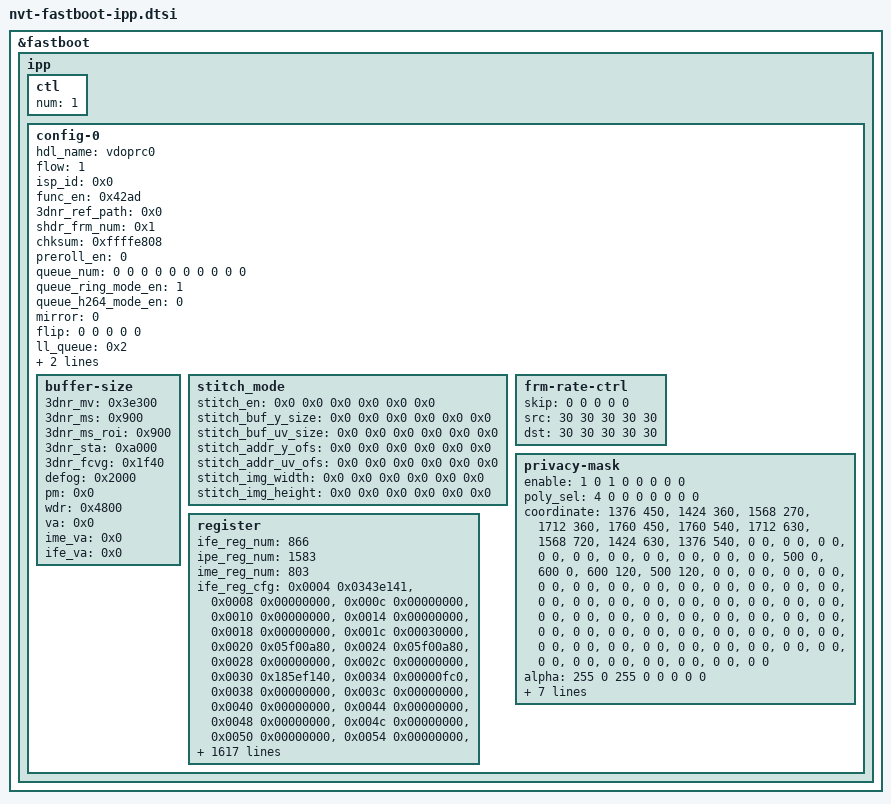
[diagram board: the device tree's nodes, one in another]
&fastboot {
	ipp {
		ctl {
			num = <1>;
		};
		config-0 {
			hdl_name = "vdoprc0";
			flow = <1>;
			isp_id = <0x0>;
			func_en = <0x42ad>;
			3dnr_ref_path = <0x0>;
			shdr_frm_num = <0x1>;
			chksum = <0xffffe808>;
			preroll_en = <0>;
			queue_num = <0 0 0 0 0 0 0 0 0 0 >;
			queue_ring_mode_en = <1>;
			queue_h264_mode_en = <0>;
			mirror = <0>;
			flip = <0 0 0 0 0 >;
			ll_queue = <0x2>;
			rtos_queue = <0x2>;
			buffer_func_en = <0x42ad>;
			buffer-size {
				3dnr_mv = <0x3e300>;
				3dnr_ms = <0x900>;
				3dnr_ms_roi = <0x900>;
				3dnr_sta = <0xa000>;
				3dnr_fcvg = <0x1f40>;
				defog = <0x2000>;
				pm = <0x0>;
				wdr = <0x4800>;
				va = <0x0>;
				ime_va = <0x0>;
				ife_va = <0x0>;
			};
			stitch_mode {
				stitch_en = <0x0 0x0 0x0 0x0 0x0 0x0>;
				stitch_buf_y_size = <0x0 0x0 0x0 0x0 0x0 0x0>;
				stitch_buf_uv_size = <0x0 0x0 0x0 0x0 0x0 0x0>;
				stitch_addr_y_ofs = <0x0 0x0 0x0 0x0 0x0 0x0>;
				stitch_addr_uv_ofs = <0x0 0x0 0x0 0x0 0x0 0x0>;
				stitch_img_width = <0x0 0x0 0x0 0x0 0x0 0x0>;
				stitch_img_height = <0x0 0x0 0x0 0x0 0x0 0x0>;
			};
			frm-rate-ctrl {
				skip = <0 0 0 0 0 >;
				src = <30 30 30 30 30 >;
				dst = <30 30 30 30 30 >;
			};
			privacy-mask {
				enable = <1 0 1 0 0 0 0 0>;
				poly_sel = <4 0 0 0 0 0 0 0>;
				coordinate =
					<1376 450>, <1424 360>, <1568 270>, <1712 360>, <1760 450>, <1760 540>, <1712 630>, <1568 720>, <1424 630>, <1376 540>,
					<0 0>, <0 0>, <0 0>, <0 0>, <0 0>, <0 0>, <0 0>, <0 0>, <0 0>, <0 0>,
					<500 0>, <600 0>, <600 120>, <500 120>, <0 0>, <0 0>, <0 0>, <0 0>, <0 0>, <0 0>,
					<0 0>, <0 0>, <0 0>, <0 0>, <0 0>, <0 0>, <0 0>, <0 0>, <0 0>, <0 0>,
					<0 0>, <0 0>, <0 0>, <0 0>, <0 0>, <0 0>, <0 0>, <0 0>, <0 0>, <0 0>,
					<0 0>, <0 0>, <0 0>, <0 0>, <0 0>, <0 0>, <0 0>, <0 0>, <0 0>, <0 0>,
					<0 0>, <0 0>, <0 0>, <0 0>, <0 0>, <0 0>, <0 0>, <0 0>, <0 0>, <0 0>,
					<0 0>, <0 0>, <0 0>, <0 0>, <0 0>, <0 0>, <0 0>, <0 0>, <0 0>, <0 0>;
				alpha = <255 0 255 0 0 0 0 0>;
				color =
					<78 85 255>,
					<0 0 0>,
					<147 42 20>,
					<0 0 0>,
					<0 0 0>,
					<0 0 0>,
					<0 0 0>,
					<0 0 0>;
				hlw_coordinate =
					<0 0>, <0 0>, <0 0>, <0 0>,
					<0 0>, <0 0>, <0 0>, <0 0>,
					<505 5>, <595 5>, <595 115>, <505 115>,
					<0 0>, <0 0>, <0 0>, <0 0>,
					<0 0>, <0 0>, <0 0>, <0 0>,
					<0 0>, <0 0>, <0 0>, <0 0>,
					<0 0>, <0 0>, <0 0>, <0 0>,
					<0 0>, <0 0>, <0 0>, <0 0>;
			};
			register {
			  ife_reg_num = <866>;
			  ipe_reg_num = <1583>;
			  ime_reg_num = <803>;

			  ife_reg_cfg = 
			    <0x0004 0x0343e141>,
			    <0x0008 0x00000000>,
			    <0x000c 0x00000000>,
			    <0x0010 0x00000000>,
			    <0x0014 0x00000000>,
			    <0x0018 0x00000000>,
			    <0x001c 0x00030000>,
			    <0x0020 0x05f00a80>,
			    <0x0024 0x05f00a80>,
			    <0x0028 0x00000000>,
			    <0x002c 0x00000000>,
			    <0x0030 0x185ef140>,
			    <0x0034 0x00000fc0>,
			    <0x0038 0x00000000>,
			    <0x003c 0x00000000>,
			    <0x0040 0x00000000>,
			    <0x0044 0x00000000>,
			    <0x0048 0x00000000>,
			    <0x004c 0x00000000>,
			    <0x0050 0x00000000>,
			    <0x0054 0x00000000>,
			    <0x0058 0x00000000>,
			    <0x005c 0x00000000>,
			    <0x0060 0x80000002>,
			    <0x0064 0x00000000>,
			    <0x0068 0x00000000>,
			    <0x006c 0x00000100>,
			    <0x0070 0x000fff00>,
			    <0x0074 0x011201bd>,
			    <0x0078 0x02460112>,
			    <0x007c 0x00000112>,
			    <0x0080 0x01000100>,
			    <0x0084 0x01000100>,
			    <0x0088 0x00000100>,
			    <0x008c 0x01000100>,
			    <0x0090 0x01000100>,
			    <0x0094 0x00000100>,
			    <0x0098 0x00000000>,
			    <0x009c 0x00000000>,
			    <0x00a0 0x00000000>,
			    <0x00a4 0x00000000>,
			    <0x00a8 0x00000000>,
			    <0x00ac 0x00000000>,
			    <0x00b0 0x01000100>,
			    <0x00b4 0x01000100>,
			    <0x00b8 0x00000100>,
			    <0x00bc 0x00000000>,
			    <0x00c0 0x00000000>,
			    <0x00c4 0x00000000>,
			    <0x00c8 0x00000000>,
			    <0x00cc 0x00000000>,
			    <0x00d0 0x00000000>,
			    <0x00d4 0x00000000>,
			    <0x00d8 0x00000000>,
			    <0x00dc 0x00000000>,
			    <0x00e0 0x00000000>,
			    <0x00e4 0x00000000>,
			    <0x00e8 0x00000000>,
			    <0x00ec 0x00000000>,
			    <0x00f0 0x0000ffff>,
			    <0x00f4 0x00000000>,
			    <0x00f8 0x00000000>,
			    <0x00fc 0x00000000>,
			    <0x0100 0x00080040>,
			    <0x0104 0x00000000>,
			    <0x0108 0x0911171f>,
			    <0x010c 0x00000307>,
			    <0x0110 0x00000000>,
			    <0x0114 0x00010001>,
			    <0x0118 0x00020001>,
			    <0x011c 0x00000000>,
			    <0x0120 0x00000000>,
			    <0x0124 0x00010001>,
			    <0x0128 0x00020001>,
			    <0x012c 0x00000000>,
			    <0x0130 0x00000000>,
			    <0x0134 0x00010001>,
			    <0x0138 0x00020001>,
			    <0x013c 0x00000000>,
			    <0x0140 0x00000000>,
			    <0x0144 0x00010001>,
			    <0x0148 0x00020001>,
			    <0x014c 0x00000000>,
			    <0x0150 0x00010000>,
			    <0x0154 0x00040003>,
			    <0x0158 0x00070004>,
			    <0x015c 0x00000000>,
			    <0x0160 0x00010000>,
			    <0x0164 0x00040003>,
			    <0x0168 0x00070004>,
			    <0x016c 0x00000000>,
			    <0x0170 0x00010000>,
			    <0x0174 0x00040003>,
			    <0x0178 0x00070004>,
			    <0x017c 0x00000000>,
			    <0x0180 0x00010000>,
			    <0x0184 0x00040003>,
			    <0x0188 0x00070004>,
			    <0x018c 0x00000000>,
			    <0x0190 0x002c62c6>,
			    <0x0194 0x0040c40c>,
			    <0x0198 0x006af6af>,
			    <0x019c 0x0093d93d>,
			    <0x01a0 0x00f41f41>,
			    <0x01a4 0x00010000>,
			    <0x01a8 0x00010033>,
			    <0x01ac 0x86543210>,
			    <0x01b0 0x86543210>,
			    <0x01b4 0x00f00001>,
			    <0x01b8 0x008000a0>,
			    <0x01bc 0x000010ff>,
			    <0x01c0 0x00020000>,
			    <0x01c4 0x00030002>,
			    <0x01c8 0x00040004>,
			    <0x01cc 0x00050004>,
			    <0x01d0 0x00060005>,
			    <0x01d4 0x00060006>,
			    <0x01d8 0x00070006>,
			    <0x01dc 0x00070007>,
			    <0x01e0 0x00000008>,
			    <0x01e4 0x00020000>,
			    <0x01e8 0x00030002>,
			    <0x01ec 0x00040004>,
			    <0x01f0 0x00050004>,
			    <0x01f4 0x00060005>,
			    <0x01f8 0x00060006>,
			    <0x01fc 0x00070006>,
			    <0x0200 0x00070007>,
			    <0x0204 0x00000008>,
			    <0x0208 0x00020000>,
			    <0x020c 0x00030002>,
			    <0x0210 0x00040004>,
			    <0x0214 0x00050004>,
			    <0x0218 0x00060005>,
			    <0x021c 0x00060006>,
			    <0x0220 0x00070006>,
			    <0x0224 0x00070007>,
			    <0x0228 0x00000008>,
			    <0x022c 0x00020000>,
			    <0x0230 0x00030002>,
			    <0x0234 0x00040004>,
			    <0x0238 0x00050004>,
			    <0x023c 0x00060005>,
			    <0x0240 0x00060006>,
			    <0x0244 0x00070006>,
			    <0x0248 0x00070007>,
			    <0x024c 0x00000008>,
			    <0x0250 0x00020000>,
			    <0x0254 0x00030002>,
			    <0x0258 0x00040004>,
			    <0x025c 0x00050004>,
			    <0x0260 0x00060005>,
			    <0x0264 0x00060006>,
			    <0x0268 0x00070006>,
			    <0x026c 0x00070007>,
			    <0x0270 0x00000008>,
			    <0x0274 0x00020000>,
			    <0x0278 0x00030002>,
			    <0x027c 0x00040004>,
			    <0x0280 0x00050004>,
			    <0x0284 0x00060005>,
			    <0x0288 0x00060006>,
			    <0x028c 0x00070006>,
			    <0x0290 0x00070007>,
			    <0x0294 0x00000008>,
			    <0x0298 0x00020000>,
			    <0x029c 0x00030002>,
			    <0x02a0 0x00040004>,
			    <0x02a4 0x00050004>,
			    <0x02a8 0x00060005>,
			    <0x02ac 0x00060006>,
			    <0x02b0 0x00070006>,
			    <0x02b4 0x00070007>,
			    <0x02b8 0x00000008>,
			    <0x02bc 0x00020000>,
			    <0x02c0 0x00030002>,
			    <0x02c4 0x00040004>,
			    <0x02c8 0x00050004>,
			    <0x02cc 0x00060005>,
			    <0x02d0 0x00060006>,
			    <0x02d4 0x00070006>,
			    <0x02d8 0x00070007>,
			    <0x02dc 0x00000008>,
			    <0x02e0 0x02f80540>,
			    <0x02e4 0x02f80540>,
			    <0x02e8 0x02f80540>,
			    <0x02ec 0x02f80540>,
			    <0x02f0 0x002a52a7>,
			    <0x02f4 0x00000001>,
			    <0x02f8 0x00000000>,
			    <0x02fc 0x00000000>,
			    <0x0300 0x00000000>,
			    <0x0304 0x00000000>,
			    <0x0308 0x00000000>,
			    <0x030c 0x00000000>,
			    <0x0310 0x00000000>,
			    <0x0314 0x00000000>,
			    <0x0318 0x00000000>,
			    <0x031c 0x00000000>,
			    <0x0320 0x00000000>,
			    <0x0324 0x00000000>,
			    <0x0328 0x00000000>,
			    <0x032c 0x00000000>,
			    <0x0330 0x00000000>,
			    <0x0334 0x00000000>,
			    <0x0338 0x00000000>,
			    <0x033c 0x00000000>,
			    <0x0340 0x00000000>,
			    <0x0344 0x00000000>,
			    <0x0348 0x00000000>,
			    <0x034c 0x00000000>,
			    <0x0350 0x00000000>,
			    <0x0354 0x00000000>,
			    <0x0358 0x00000000>,
			    <0x035c 0x00000000>,
			    <0x0360 0x00000000>,
			    <0x0364 0x00000000>,
			    <0x0368 0x00000000>,
			    <0x036c 0x00000000>,
			    <0x0370 0x00000000>,
			    <0x0374 0x00000000>,
			    <0x0378 0x00000000>,
			    <0x037c 0x00000000>,
			    <0x0380 0x00000000>,
			    <0x0384 0x00000000>,
			    <0x0388 0x09060301>,
			    <0x038c 0x15120f0d>,
			    <0x0390 0x211e1b18>,
			    <0x0394 0x2d2a2724>,
			    <0x0398 0x00000030>,
			    <0x039c 0x1b181000>,
			    <0x03a0 0x1f1e1c1b>,
			    <0x03a4 0x1c1d1e1f>,
			    <0x03a8 0x0c1a1b1c>,
			    <0x03ac 0x00000004>,
			    <0x03b0 0x00000000>,
			    <0x03b4 0x00000000>,
			    <0x03b8 0x00000000>,
			    <0x03bc 0x00000000>,
			    <0x03c0 0x1f1f1f1f>,
			    <0x03c4 0x1e1e1f1f>,
			    <0x03c8 0x14181c1d>,
			    <0x03cc 0x080a0c10>,
			    <0x03d0 0x06060606>,
			    <0x03d4 0x05050505>,
			    <0x03d8 0x04040404>,
			    <0x03dc 0x20010203>,
			    <0x03e0 0x00000000>,
			    <0x03e4 0x00000000>,
			    <0x03e8 0x00000000>,
			    <0x03ec 0x00000000>,
			    <0x03f0 0x00000000>,
			    <0x03f4 0x00000000>,
			    <0x03f8 0x00000000>,
			    <0x03fc 0x00000000>,
			    <0x0400 0x00000000>,
			    <0x0404 0x00000000>,
			    <0x0408 0x00000000>,
			    <0x040c 0x00000000>,
			    <0x0410 0x00000000>,
			    <0x0414 0x00000000>,
			    <0x0418 0x00000000>,
			    <0x041c 0x00000000>,
			    <0x0420 0x00000000>,
			    <0x0424 0x00000000>,
			    <0x0428 0x00000000>,
			    <0x042c 0x00000000>,
			    <0x0430 0x00000000>,
			    <0x0434 0x00000000>,
			    <0x0438 0x00000000>,
			    <0x043c 0x00000000>,
			    <0x0440 0x00000000>,
			    <0x0444 0x00000000>,
			    <0x0448 0x00000000>,
			    <0x044c 0x00000000>,
			    <0x0450 0x00000000>,
			    <0x0454 0x00000000>,
			    <0x0458 0x00000000>,
			    <0x045c 0x00000000>,
			    <0x0460 0x00000000>,
			    <0x0464 0x00000000>,
			    <0x0468 0x00000000>,
			    <0x046c 0x00000000>,
			    <0x0470 0x00000000>,
			    <0x0474 0x00000000>,
			    <0x0478 0x00000000>,
			    <0x047c 0x00000000>,
			    <0x0480 0x00000000>,
			    <0x0484 0x00000000>,
			    <0x0488 0x00000000>,
			    <0x048c 0x00000000>,
			    <0x0490 0x00000000>,
			    <0x0494 0x00000000>,
			    <0x0498 0x00000000>,
			    <0x049c 0x00000000>,
			    <0x04a0 0x00000000>,
			    <0x04a4 0x00000000>,
			    <0x04a8 0x00000000>,
			    <0x04ac 0x00000000>,
			    <0x04b0 0x00000000>,
			    <0x04b4 0x00000000>,
			    <0x04b8 0x00000000>,
			    <0x04bc 0x00000000>,
			    <0x04c0 0x00000000>,
			    <0x04c4 0x00000000>,
			    <0x04c8 0x00000000>,
			    <0x04cc 0x00000000>,
			    <0x04d0 0x00000000>,
			    <0x04d4 0x00000000>,
			    <0x04d8 0x00000000>,
			    <0x04dc 0x00000000>,
			    <0x04e0 0x00000000>,
			    <0x04e4 0x00000000>,
			    <0x04e8 0x00000000>,
			    <0x04ec 0x00000000>,
			    <0x04f0 0x00000000>,
			    <0x04f4 0x00000000>,
			    <0x04f8 0x00000000>,
			    <0x04fc 0x00000000>,
			    <0x0500 0x00000000>,
			    <0x0504 0x00000000>,
			    <0x0508 0x00000000>,
			    <0x050c 0x00000000>,
			    <0x0510 0x00000000>,
			    <0x0514 0x00000000>,
			    <0x0518 0x00000000>,
			    <0x051c 0x00000000>,
			    <0x0520 0x00000210>,
			    <0x0524 0x02000c00>,
			    <0x0528 0x004000c0>,
			    <0x052c 0x02000c00>,
			    <0x0530 0x004000c0>,
			    <0x0534 0x40000800>,
			    <0x0538 0x40000800>,
			    <0x053c 0x00000100>,
			    <0x0540 0x00000005>,
			    <0x0544 0x0a418820>,
			    <0x0548 0x16a4a0e6>,
			    <0x054c 0x000839ac>,
			    <0x0550 0xff100fff>,
			    <0x0554 0xff100fff>,
			    <0x0558 0x00000000>,
			    <0x055c 0x00000000>,
			    <0x0560 0x00000000>,
			    <0x0564 0x00000000>,
			    <0x0568 0x00000000>,
			    <0x056c 0x00000000>,
			    <0x0570 0x00000000>,
			    <0x0574 0x00000000>,
			    <0x0578 0x00000000>,
			    <0x057c 0x00000000>,
			    <0x0580 0x00000000>,
			    <0x0584 0x00000000>,
			    <0x0588 0x00000000>,
			    <0x058c 0x00000000>,
			    <0x0590 0x00000000>,
			    <0x0594 0x00000000>,
			    <0x0598 0x00000000>,
			    <0x059c 0x00000000>,
			    <0x05a0 0x00000000>,
			    <0x05a4 0x00000000>,
			    <0x05a8 0x00000000>,
			    <0x05ac 0x00000000>,
			    <0x05b0 0x00000000>,
			    <0x05b4 0x00000000>,
			    <0x05b8 0x00000000>,
			    <0x05bc 0x00000000>,
			    <0x05c0 0x00000000>,
			    <0x05c4 0x00000000>,
			    <0x05c8 0x00000000>,
			    <0x05cc 0x00000000>,
			    <0x05d0 0x00000000>,
			    <0x05d4 0x00000000>,
			    <0x05d8 0x00000000>,
			    <0x05dc 0x00000000>,
			    <0x05e0 0x00000000>,
			    <0x05e4 0x00000000>,
			    <0x05e8 0x00000000>,
			    <0x05ec 0x00000000>,
			    <0x05f0 0x00000000>,
			    <0x05f4 0x00000000>,
			    <0x05f8 0x00000000>,
			    <0x05fc 0x00000000>,
			    <0x0600 0x00000000>,
			    <0x0604 0x00000000>,
			    <0x0608 0x00000000>,
			    <0x060c 0x00000000>,
			    <0x0610 0x00000000>,
			    <0x0614 0x00000000>,
			    <0x0618 0x00000000>,
			    <0x061c 0x00000000>,
			    <0x0620 0x00000000>,
			    <0x0624 0x00000000>,
			    <0x0628 0x00000000>,
			    <0x062c 0x00000000>,
			    <0x0630 0x00000000>,
			    <0x0634 0x00000000>,
			    <0x0638 0x00000000>,
			    <0x063c 0x00000000>,
			    <0x0640 0x00000000>,
			    <0x0644 0x00000000>,
			    <0x0648 0x00000000>,
			    <0x064c 0x00000000>,
			    <0x0650 0x00000000>,
			    <0x0654 0x00000000>,
			    <0x0658 0x00000000>,
			    <0x065c 0x00000000>,
			    <0x0660 0x00000000>,
			    <0x0664 0x00000000>,
			    <0x0668 0x00000000>,
			    <0x066c 0x00000000>,
			    <0x0670 0x00000000>,
			    <0x0674 0x00000000>,
			    <0x0678 0x00000000>,
			    <0x067c 0x00000000>,
			    <0x0680 0x00000000>,
			    <0x0684 0x00000000>,
			    <0x0688 0x00000000>,
			    <0x068c 0x00000000>,
			    <0x0690 0x00000000>,
			    <0x0694 0x00000000>,
			    <0x0698 0x00000000>,
			    <0x069c 0x00000000>,
			    <0x06a0 0x00000000>,
			    <0x06a4 0x00000000>,
			    <0x06a8 0x00000000>,
			    <0x06ac 0x00000000>,
			    <0x06b0 0x00000000>,
			    <0x06b4 0x00000000>,
			    <0x06b8 0x00000000>,
			    <0x06bc 0x00000000>,
			    <0x06c0 0x00000000>,
			    <0x06c4 0x00000000>,
			    <0x06c8 0x00000000>,
			    <0x06cc 0x00000000>,
			    <0x06d0 0x00000000>,
			    <0x06d4 0x00000000>,
			    <0x06d8 0x00000000>,
			    <0x06dc 0x00000000>,
			    <0x06e0 0x00000000>,
			    <0x06e4 0x00000000>,
			    <0x06e8 0x00000000>,
			    <0x06ec 0x00000000>,
			    <0x06f0 0x00000000>,
			    <0x06f4 0x00000000>,
			    <0x06f8 0x00000000>,
			    <0x06fc 0x00000000>,
			    <0x0700 0x00000000>,
			    <0x0704 0x00000000>,
			    <0x0708 0x00000000>,
			    <0x070c 0x00000000>,
			    <0x0710 0x01000100>,
			    <0x0714 0x01000100>,
			    <0x0718 0x00000100>,
			    <0x071c 0x00000000>,
			    <0x0720 0x00000000>,
			    <0x0724 0x00000000>,
			    <0x0728 0x00000000>,
			    <0x072c 0x00000000>,
			    <0x0730 0x00000000>,
			    <0x0734 0x00000000>,
			    <0x0738 0x00000000>,
			    <0x073c 0x00000000>,
			    <0x0740 0x00000000>,
			    <0x0744 0x00000000>,
			    <0x0748 0x00000000>,
			    <0x074c 0x00000000>,
			    <0x0750 0x00000000>,
			    <0x0754 0x00000000>,
			    <0x0758 0x00000000>,
			    <0x075c 0x00000000>,
			    <0x0760 0x00000000>,
			    <0x0764 0x00000000>,
			    <0x0768 0x00000000>,
			    <0x076c 0x00000000>,
			    <0x0770 0x00000000>,
			    <0x0774 0x00000000>,
			    <0x0778 0x00000000>,
			    <0x077c 0x00000000>,
			    <0x0780 0x00000000>,
			    <0x0784 0x00000000>,
			    <0x0788 0x00000000>,
			    <0x078c 0x00000000>,
			    <0x0790 0x00000000>,
			    <0x0794 0x00000000>,
			    <0x0798 0x00000000>,
			    <0x079c 0x00000000>,
			    <0x07a0 0x00000000>,
			    <0x07a4 0x00000000>,
			    <0x07a8 0x00000000>,
			    <0x07ac 0x00000000>,
			    <0x07b0 0x00000000>,
			    <0x07b4 0x00000000>,
			    <0x07b8 0x00000000>,
			    <0x07bc 0x00000000>,
			    <0x07c0 0x00000000>,
			    <0x07c4 0x00000000>,
			    <0x07c8 0x00000000>,
			    <0x07cc 0x00000000>,
			    <0x07d0 0x00000000>,
			    <0x07d4 0x00000000>,
			    <0x07d8 0x00000000>,
			    <0x07dc 0x00000000>,
			    <0x07e0 0x00000000>,
			    <0x07e4 0x00000000>,
			    <0x07e8 0x00000000>,
			    <0x07ec 0x00000000>,
			    <0x07f0 0x00000000>,
			    <0x07f4 0x00000000>,
			    <0x07f8 0x00000000>,
			    <0x07fc 0x00000000>,
			    <0x0800 0x00000000>,
			    <0x0804 0x00000000>,
			    <0x0808 0x00000000>,
			    <0x080c 0x00000000>,
			    <0x0810 0x00000000>,
			    <0x0814 0x00000000>,
			    <0x0818 0x00000000>,
			    <0x081c 0x00000000>,
			    <0x0820 0x00000000>,
			    <0x0824 0x00000000>,
			    <0x0828 0x00000000>,
			    <0x082c 0x00000000>,
			    <0x0830 0x00000000>,
			    <0x0834 0x00000000>,
			    <0x0838 0x000002a0>,
			    <0x083c 0x00000000>,
			    <0x0840 0x00000000>,
			    <0x0844 0x00000000>,
			    <0x0848 0x00000000>,
			    <0x084c 0x00000000>,
			    <0x0850 0x00000000>,
			    <0x0854 0x00000000>,
			    <0x0858 0x00000000>,
			    <0x085c 0x00000000>,
			    <0x0860 0x00000007>,
			    <0x0864 0x0f7201ae>,
			    <0x0868 0x0f9e0fe0>,
			    <0x086c 0x0fe6017e>,
			    <0x0870 0x0ef10034>,
			    <0x0874 0x000001db>,
			    <0x0878 0x00000000>,
			    <0x087c 0x725a3c00>,
			    <0x0880 0xab9f9183>,
			    <0x0884 0xd6ccc2b7>,
			    <0x0888 0xf8f0e8df>,
			    <0x088c 0x000000ff>,
			    <0x0890 0x00000000>,
			    <0x0894 0x00000000>,
			    <0x0898 0x00000000>,
			    <0x089c 0x00000000>,
			    <0x08a0 0x00000000>,
			    <0x08a4 0x00000000>,
			    <0x08a8 0x00000000>,
			    <0x08ac 0x00000000>,
			    <0x08b0 0x00000000>,
			    <0x08b4 0x00000000>,
			    <0x08b8 0x00000000>,
			    <0x08bc 0x00000000>,
			    <0x08c0 0x00000000>,
			    <0x08c4 0x00000000>,
			    <0x08c8 0x00000000>,
			    <0x08cc 0x00000000>,
			    <0x08d0 0x00000000>,
			    <0x08d4 0x00000000>,
			    <0x08d8 0x00000000>,
			    <0x08dc 0x00000000>,
			    <0x08e0 0x00000000>,
			    <0x08e4 0x00000000>,
			    <0x08e8 0x00000000>,
			    <0x08ec 0x00000000>,
			    <0x08f0 0x00000000>,
			    <0x08f4 0x00000000>,
			    <0x08f8 0x00000000>,
			    <0x08fc 0x00000000>,
			    <0x0900 0x0000000f>,
			    <0x0904 0x000b111f>,
			    <0x0908 0x1afd4880>,
			    <0x090c 0x00000100>,
			    <0x0910 0x1afd9080>,
			    <0x0914 0x00000100>,
			    <0x0918 0x151c1500>,
			    <0x091c 0x0000030c>,
			    <0x0920 0x00000308>,
			    <0x0924 0x00000000>,
			    <0x0928 0x00000000>,
			    <0x092c 0x00000000>,
			    <0x0930 0x00000000>,
			    <0x0934 0x00000000>,
			    <0x0938 0x00000000>,
			    <0x093c 0x00000054>,
			    <0x0940 0x1565193c>,
			    <0x0944 0x160c160c>,
			    <0x0948 0x55050003>,
			    <0x094c 0x00000000>,
			    <0x0950 0x00000000>,
			    <0x0954 0x00000000>,
			    <0x0958 0x00000000>,
			    <0x095c 0x00000000>,
			    <0x0960 0x00000000>,
			    <0x0964 0x00000000>,
			    <0x0968 0x00000000>,
			    <0x096c 0x00000000>,
			    <0x0970 0x00000000>,
			    <0x0974 0x00000000>,
			    <0x0978 0x00000000>,
			    <0x097c 0x00000000>,
			    <0x0980 0x00000000>,
			    <0x0984 0x00000000>,
			    <0x0988 0x00000000>,
			    <0x098c 0x00000000>,
			    <0x0990 0x00000000>,
			    <0x0994 0x00000000>,
			    <0x0998 0x00000000>,
			    <0x099c 0x00000000>,
			    <0x09a0 0x00000000>,
			    <0x09a4 0x00000000>,
			    <0x09a8 0x00000000>,
			    <0x09ac 0x00000000>,
			    <0x09b0 0x00000000>,
			    <0x09b4 0x00000000>,
			    <0x09b8 0x00000000>,
			    <0x09bc 0x00000000>,
			    <0x09c0 0x00000000>,
			    <0x09c4 0x00000000>,
			    <0x09c8 0x00000000>,
			    <0x09cc 0x00000000>,
			    <0x09d0 0x00000000>,
			    <0x09d4 0x00000000>,
			    <0x09d8 0x00000000>,
			    <0x09dc 0x00000000>,
			    <0x09e0 0x00000000>,
			    <0x09e4 0x00000000>,
			    <0x09e8 0x00000000>,
			    <0x09ec 0x00000000>,
			    <0x09f0 0x00000000>,
			    <0x09f4 0x00000000>,
			    <0x09f8 0x0fb00fb5>,
			    <0x09fc 0x0fa50fab>,
			    <0x0a00 0x0f9a0fa0>,
			    <0x0a04 0x0f8c0f93>,
			    <0x0a08 0x0f7d0f85>,
			    <0x0a0c 0x0f6c0f74>,
			    <0x0a10 0x0f580f62>,
			    <0x0a14 0x0f430f4e>,
			    <0x0a18 0x0f2a0f37>,
			    <0x0a1c 0x0f0f0f1d>,
			    <0x0a20 0x0ef10f00>,
			    <0x0a24 0x0ecf0ee0>,
			    <0x0a28 0x0ea90ebc>,
			    <0x0a2c 0x0e7f0e94>,
			    <0x0a30 0x0e500e68>,
			    <0x0a34 0x0e1c0e37>,
			    <0x0a38 0x0de40e01>,
			    <0x0a3c 0x0da50dc5>,
			    <0x0a40 0x0d620d84>,
			    <0x0a44 0x0d180d3d>,
			    <0x0a48 0x0cc80cf0>,
			    <0x0a4c 0x0c710c9d>,
			    <0x0a50 0x0c150c44>,
			    <0x0a54 0x0bb20be4>,
			    <0x0a58 0x0b4a0b7f>,
			    <0x0a5c 0x0adc0b14>,
			    <0x0a60 0x0a6a0aa4>,
			    <0x0a64 0x09f30a2f>,
			    <0x0a68 0x097809b6>,
			    <0x0a6c 0x08fb093a>,
			    <0x0a70 0x087c08bc>,
			    <0x0a74 0x07fc083c>,
			    <0x0a78 0x000007bc>,
			    <0x0a7c 0x06bf07bc>,
			    <0x0a80 0x04ea05cc>,
			    <0x0a84 0x0366041c>,
			    <0x0a88 0x024302c9>,
			    <0x0a8c 0x017601d3>,
			    <0x0a90 0x00ee012b>,
			    <0x0a94 0x009500bc>,
			    <0x0a98 0x005d0076>,
			    <0x0a9c 0x00000049>,
			    <0x0aa0 0x00000000>,
			    <0x0aa4 0x00000040>,
			    <0x0aa8 0xff000000>,
			    <0x0aac 0x00408003>,
			    <0x0ab0 0x00000200>,
			    <0x0ab4 0x00060006>,
			    <0x0ab8 0x00000000>,
			    <0x0abc 0x00000000>,
			    <0x0ac0 0x00000000>,
			    <0x0ac4 0x00000000>,
			    <0x0ac8 0x00000000>,
			    <0x0acc 0x00000000>,
			    <0x0ad0 0x00000000>,
			    <0x0ad4 0x00000000>,
			    <0x0ad8 0x00000000>,
			    <0x0adc 0x00000000>,
			    <0x0ae0 0x00000000>,
			    <0x0ae4 0x00000000>,
			    <0x0ae8 0x00000000>,
			    <0x0aec 0x00000000>,
			    <0x0af0 0x00000000>,
			    <0x0af4 0x00000000>,
			    <0x0af8 0x00000000>,
			    <0x0afc 0x00000000>,
			    <0x0b00 0x00000000>,
			    <0x0b04 0x00000000>,
			    <0x0b08 0x00000000>,
			    <0x0b0c 0x00000000>,
			    <0x0b10 0x00000000>,
			    <0x0b14 0x00000000>,
			    <0x0b18 0x00000000>,
			    <0x0b1c 0x00000000>,
			    <0x0b20 0x00000000>,
			    <0x0b24 0x00000000>,
			    <0x0b28 0x00000000>,
			    <0x0b2c 0x00000000>,
			    <0x0b30 0x00000000>,
			    <0x0b34 0x00000000>,
			    <0x0b38 0x00000000>,
			    <0x0b3c 0x00000000>,
			    <0x0b40 0x00000000>,
			    <0x0b44 0x00000000>,
			    <0x0b48 0x00000000>,
			    <0x0b4c 0x00000000>,
			    <0x0b50 0x00000000>,
			    <0x0b54 0x00000000>,
			    <0x0b58 0x00000000>,
			    <0x0b5c 0x00000000>,
			    <0x0b60 0x00000000>,
			    <0x0b64 0x00000000>,
			    <0x0b68 0x00000000>,
			    <0x0b6c 0x00000000>,
			    <0x0b70 0x00000000>,
			    <0x0b74 0x00000000>,
			    <0x0b78 0x00000000>,
			    <0x0b7c 0x00000000>,
			    <0x0b80 0x00000000>,
			    <0x0b84 0x00000000>,
			    <0x0b88 0x00000000>,
			    <0x0b8c 0x00000000>,
			    <0x0b90 0x00000000>,
			    <0x0b94 0x00000000>,
			    <0x0b98 0x00000000>,
			    <0x0b9c 0x00000000>,
			    <0x0ba0 0x00000000>,
			    <0x0ba4 0x00000000>,
			    <0x0ba8 0x00000000>,
			    <0x0bac 0x00000000>,
			    <0x0bb0 0x00000000>,
			    <0x0bb4 0x00000000>,
			    <0x0bb8 0x06008001>,
			    <0x0bbc 0x0a000800>,
			    <0x0bc0 0x0c800c00>,
			    <0x0bc4 0x00000dac>,
			    <0x0bc8 0x00000000>,
			    <0x0bcc 0x00000000>,
			    <0x0bd0 0x00000000>,
			    <0x0bd4 0x00000000>,
			    <0x0bd8 0x00000000>,
			    <0x0bdc 0x00000000>,
			    <0x0be0 0x00000000>,
			    <0x0be4 0x00000000>,
			    <0x0be8 0x00000000>,
			    <0x0bec 0x00000000>,
			    <0x0bf0 0x00000000>,
			    <0x0bf4 0x00000000>,
			    <0x0bf8 0x00000000>,
			    <0x0bfc 0x00000000>,
			    <0x0c00 0x00000000>,
			    <0x0c04 0x00000000>,
			    <0x0c08 0x00000000>,
			    <0x0c0c 0x00000000>,
			    <0x0c10 0x00000000>,
			    <0x0c14 0x00000000>,
			    <0x0c18 0x00000000>,
			    <0x0c1c 0x00000000>,
			    <0x0c20 0x00000000>,
			    <0x0c24 0x00000000>,
			    <0x0c28 0x00000000>,
			    <0x0c2c 0x00000000>,
			    <0x0c30 0x00000000>,
			    <0x0c34 0x00000000>,
			    <0x0c38 0x00000000>,
			    <0x0c3c 0x00000000>,
			    <0x0c40 0x00000000>,
			    <0x0c44 0x00000000>,
			    <0x0c48 0x00000000>,
			    <0x0c4c 0x00000000>,
			    <0x0c50 0x00000000>,
			    <0x0c54 0x00000000>,
			    <0x0c58 0x00000000>,
			    <0x0c5c 0x00000000>,
			    <0x0c60 0x00000000>,
			    <0x0c64 0x00000000>,
			    <0x0c68 0x00000000>,
			    <0x0c6c 0x00000000>,
			    <0x0c70 0x00000000>,
			    <0x0c74 0x00000000>,
			    <0x0c78 0x00000000>,
			    <0x0c7c 0x00000000>,
			    <0x0c80 0x00000000>,
			    <0x0c84 0x00000000>,
			    <0x0c88 0x00000000>,
			    <0x0c8c 0x00000000>,
			    <0x0c90 0x00000000>,
			    <0x0c94 0x00000000>,
			    <0x0c98 0x00000000>,
			    <0x0c9c 0x00000000>,
			    <0x0ca0 0x00000000>,
			    <0x0ca4 0x00000000>,
			    <0x0ca8 0x00000000>,
			    <0x0cac 0x00000000>,
			    <0x0cb0 0x00000000>,
			    <0x0cb4 0x00000000>,
			    <0x0cb8 0x00000000>,
			    <0x0cbc 0x00000000>,
			    <0x0cc0 0x00000000>,
			    <0x0cc4 0x00000000>,
			    <0x0cc8 0x00000000>,
			    <0x0ccc 0x00000000>,
			    <0x0cd0 0x00000000>,
			    <0x0cd4 0x00000000>,
			    <0x0cd8 0x00000000>,
			    <0x0cdc 0x00000000>,
			    <0x0ce0 0x00000000>,
			    <0x0ce4 0x00000000>,
			    <0x0ce8 0x00000000>,
			    <0x0cec 0x00000000>,
			    <0x0cf0 0x00000000>,
			    <0x0cf4 0x00000000>,
			    <0x0cf8 0x00000000>,
			    <0x0cfc 0x00000000>,
			    <0x0d00 0x00000000>,
			    <0x0d04 0x00000000>,
			    <0x0d08 0x00000000>,
			    <0x0d0c 0x00000000>,
			    <0x0d10 0x00000000>,
			    <0x0d14 0x00000000>,
			    <0x0d18 0x00000000>,
			    <0x0d1c 0x00000000>,
			    <0x0d20 0x00000000>,
			    <0x0d24 0x00000000>,
			    <0x0d28 0x00000000>,
			    <0x0d2c 0x00000000>,
			    <0x0d30 0x00000000>,
			    <0x0d34 0x00000000>,
			    <0x0d38 0x00000000>,
			    <0x0d3c 0x00000000>,
			    <0x0d40 0x00000000>,
			    <0x0d44 0x00000000>,
			    <0x0d48 0x00000000>,
			    <0x0d4c 0x00000000>,
			    <0x0d50 0x00000000>,
			    <0x0d54 0x00000000>,
			    <0x0d58 0x00000000>,
			    <0x0d5c 0x00000000>,
			    <0x0d60 0x00000000>,
			    <0x0d64 0x00000000>,
			    <0x0d68 0x00000000>,
			    <0x0d6c 0x00000000>,
			    <0x0d70 0x00000000>,
			    <0x0d74 0x00000000>,
			    <0x0d78 0x00000000>,
			    <0x0d7c 0x00000000>,
			    <0x0d80 0x00000000>,
			    <0x0d84 0x00000000>,
			    <0x0d88 0x00000000>;

			  ipe_reg_cfg = 
			    <0x0004 0x00000a05>,
			    <0x0008 0x00017f9b>,
			    <0x000c 0x00000088>,
			    <0x0010 0x00000000>,
			    <0x0014 0x00000000>,
			    <0x0018 0x000005f0>,
			    <0x001c 0x00000000>,
			    <0x0020 0x00000000>,
			    <0x0024 0x00000000>,
			    <0x0028 0x00000000>,
			    <0x002c 0x1aea44ec>,
			    <0x0030 0x00000000>,
			    <0x0034 0x00000000>,
			    <0x0038 0x00000000>,
			    <0x003c 0x00000000>,
			    <0x0040 0x00000000>,
			    <0x0044 0x00000000>,
			    <0x0048 0x00000000>,
			    <0x004c 0x00000000>,
			    <0x0050 0x00014208>,
			    <0x0054 0x00000000>,
			    <0x0058 0x00000000>,
			    <0x005c 0x00000000>,
			    <0x0060 0x00000000>,
			    <0x0064 0x00000000>,
			    <0x0068 0x00000000>,
			    <0x006c 0x00000000>,
			    <0x0070 0x017c05a3>,
			    <0x0074 0x3e2ec02a>,
			    <0x0078 0x00a013dd>,
			    <0x007c 0x0010100a>,
			    <0x0080 0x00181818>,
			    <0x0084 0x00000333>,
			    <0x0088 0x00010004>,
			    <0x008c 0x00008888>,
			    <0x0090 0x88881000>,
			    <0x0094 0x00082028>,
			    <0x0098 0xffc8201f>,
			    <0x009c 0x00a500b6>,
			    <0x00a0 0x00800801>,
			    <0x00a4 0xffff3180>,
			    <0x00a8 0x00010000>,
			    <0x00ac 0x01000100>,
			    <0x00b0 0x00600060>,
			    <0x00b4 0x05080000>,
			    <0x00b8 0x40352d20>,
			    <0x00bc 0x40404040>,
			    <0x00c0 0x40404040>,
			    <0x00c4 0x262c3440>,
			    <0x00c8 0x15020000>,
			    <0x00cc 0x7a573000>,
			    <0x00d0 0xffddb79a>,
			    <0x00d4 0xaac0e0ff>,
			    <0x00d8 0x8088909a>,
			    <0x00dc 0x00000000>,
			    <0x00e0 0x40400001>,
			    <0x00e4 0x0400fc00>,
			    <0x00e8 0x00005020>,
			    <0x00ec 0x0810e032>,
			    <0x00f0 0x41000804>,
			    <0x00f4 0x41000804>,
			    <0x00f8 0x41000804>,
			    <0x00fc 0x00000000>,
			    <0x0100 0x01ae0001>,
			    <0x0104 0x0fe00f72>,
			    <0x0108 0x017e0f9e>,
			    <0x010c 0x00340fe6>,
			    <0x0110 0x01db0ef1>,
			    <0x0114 0x00104080>,
			    <0x0118 0x00000000>,
			    <0x011c 0x00000000>,
			    <0x0120 0x00000000>,
			    <0x0124 0x050a0f14>,
			    <0x0128 0x00000000>,
			    <0x012c 0x00000000>,
			    <0x0130 0x0f0a0500>,
			    <0x0134 0x00000000>,
			    <0x0138 0x10752c4d>,
			    <0x013c 0x120357d5>,
			    <0x0140 0x07af2a80>,
			    <0x0144 0x00000000>,
			    <0x0148 0x28200000>,
			    <0x014c 0x80808080>,
			    <0x0150 0x80808080>,
			    <0x0154 0x80808080>,
			    <0x0158 0x80808080>,
			    <0x015c 0x80808080>,
			    <0x0160 0x80808080>,
			    <0x0164 0x00000000>,
			    <0x0168 0x00000000>,
			    <0x016c 0x00000000>,
			    <0x0170 0x00000000>,
			    <0x0174 0x00000000>,
			    <0x0178 0x00000000>,
			    <0x017c 0x00000000>,
			    <0x0180 0x00000000>,
			    <0x0184 0x00000000>,
			    <0x0188 0x00000000>,
			    <0x018c 0x00000000>,
			    <0x0190 0x00000000>,
			    <0x0194 0x80808080>,
			    <0x0198 0x80808080>,
			    <0x019c 0x80808080>,
			    <0x01a0 0x80808080>,
			    <0x01a4 0x80808080>,
			    <0x01a8 0x80808080>,
			    <0x01ac 0x00820820>,
			    <0x01b0 0x00820820>,
			    <0x01b4 0x00000000>,
			    <0x01b8 0x0002308c>,
			    <0x01bc 0x00000080>,
			    <0x01c0 0x00000000>,
			    <0x01c4 0x00000000>,
			    <0x01c8 0x00ffffff>,
			    <0x01cc 0x00808080>,
			    <0x01d0 0x00000000>,
			    <0x01d4 0x00000000>,
			    <0x01d8 0x00000000>,
			    <0x01dc 0x08020080>,
			    <0x01e0 0x08020080>,
			    <0x01e4 0x08020080>,
			    <0x01e8 0x08020080>,
			    <0x01ec 0x08020080>,
			    <0x01f0 0x00020080>,
			    <0x01f4 0x00000000>,
			    <0x01f8 0x02020202>,
			    <0x01fc 0x00500000>,
			    <0x0200 0x30044301>,
			    <0x0204 0x00000000>,
			    <0x0208 0x00000000>,
			    <0x020c 0x00000000>,
			    <0x0210 0x00000000>,
			    <0x0214 0x00000000>,
			    <0x0218 0x00000000>,
			    <0x021c 0x00000000>,
			    <0x0220 0x00000000>,
			    <0x0224 0x00000000>,
			    <0x0228 0x00000000>,
			    <0x022c 0x00000000>,
			    <0x0230 0x00000000>,
			    <0x0234 0x00000000>,
			    <0x0238 0x00000000>,
			    <0x023c 0x00000000>,
			    <0x0240 0x00000000>,
			    <0x0244 0x00000000>,
			    <0x0248 0x00000000>,
			    <0x024c 0x00000000>,
			    <0x0250 0x00000000>,
			    <0x0254 0x00000000>,
			    <0x0258 0x00000000>,
			    <0x025c 0x00000000>,
			    <0x0260 0x00000000>,
			    <0x0264 0x00000000>,
			    <0x0268 0x00000000>,
			    <0x026c 0x00000000>,
			    <0x0270 0x00000000>,
			    <0x0274 0x00000000>,
			    <0x0278 0x00000000>,
			    <0x027c 0x00000000>,
			    <0x0280 0x00000000>,
			    <0x0284 0x00000000>,
			    <0x0288 0x00000000>,
			    <0x028c 0x00000000>,
			    <0x0290 0x00000000>,
			    <0x0294 0x00000000>,
			    <0x0298 0x00000000>,
			    <0x029c 0x00000000>,
			    <0x02a0 0x00000000>,
			    <0x02a4 0x00000000>,
			    <0x02a8 0x00000000>,
			    <0x02ac 0x00000000>,
			    <0x02b0 0x00000000>,
			    <0x02b4 0x00000000>,
			    <0x02b8 0x00000000>,
			    <0x02bc 0x00000000>,
			    <0x02c0 0x00000000>,
			    <0x02c4 0x00000000>,
			    <0x02c8 0x00000000>,
			    <0x02cc 0x00000000>,
			    <0x02d0 0x00000000>,
			    <0x02d4 0x00000000>,
			    <0x02d8 0x00000000>,
			    <0x02dc 0x00000000>,
			    <0x02e0 0x00000000>,
			    <0x02e4 0x00000000>,
			    <0x02e8 0x00000000>,
			    <0x02ec 0x00000000>,
			    <0x02f0 0x00000000>,
			    <0x02f4 0x00000000>,
			    <0x02f8 0x00000000>,
			    <0x02fc 0x00000000>,
			    <0x0300 0x00000000>,
			    <0x0304 0x00000000>,
			    <0x0308 0x00000000>,
			    <0x030c 0x00000000>,
			    <0x0310 0x0000023f>,
			    <0x0314 0x1afd0880>,
			    <0x0318 0x00000080>,
			    <0x031c 0x1afd2880>,
			    <0x0320 0x00000080>,
			    <0x0324 0x02dd02f4>,
			    <0x0328 0x00056ad6>,
			    <0x032c 0x000595a5>,
			    <0x0330 0x00540053>,
			    <0x0334 0x00000000>,
			    <0x0338 0x00000000>,
			    <0x033c 0x00000000>,
			    <0x0340 0x00000054>,
			    <0x0344 0x00000000>,
			    <0x0348 0x00000000>,
			    <0x034c 0x00000000>,
			    <0x0350 0x00000000>,
			    <0x0354 0x00000000>,
			    <0x0358 0x00000000>,
			    <0x035c 0x00000000>,
			    <0x0360 0x00000000>,
			    <0x0364 0x00000000>,
			    <0x0368 0x00000000>,
			    <0x036c 0x00000000>,
			    <0x0370 0x00000000>,
			    <0x0374 0x00000000>,
			    <0x0378 0x00000000>,
			    <0x037c 0x00000000>,
			    <0x0380 0x00000000>,
			    <0x0384 0x00000000>,
			    <0x0388 0x00000000>,
			    <0x038c 0x00000000>,
			    <0x0390 0x00000000>,
			    <0x0394 0x00000000>,
			    <0x0398 0x00000000>,
			    <0x039c 0x00000000>,
			    <0x03a0 0x00000000>,
			    <0x03a4 0x00000000>,
			    <0x03a8 0x00000000>,
			    <0x03ac 0x00000000>,
			    <0x03b0 0x00000000>,
			    <0x03b4 0x00000000>,
			    <0x03b8 0x00000000>,
			    <0x03bc 0x00000000>,
			    <0x03c0 0x00000000>,
			    <0x03c4 0x00000000>,
			    <0x03c8 0x00000000>,
			    <0x03cc 0x00000000>,
			    <0x03d0 0x00000000>,
			    <0x03d4 0x00000000>,
			    <0x03d8 0x00000000>,
			    <0x03dc 0x00000000>,
			    <0x03e0 0x00000000>,
			    <0x03e4 0x00800000>,
			    <0x03e8 0x54545454>,
			    <0x03ec 0x54545454>,
			    <0x03f0 0x00000054>,
			    <0x03f4 0x00000000>,
			    <0x03f8 0x00000000>,
			    <0x03fc 0x00000000>,
			    <0x0400 0x00000000>,
			    <0x0404 0x00000000>,
			    <0x0408 0x00000000>,
			    <0x040c 0x00000000>,
			    <0x0410 0x00000000>,
			    <0x0414 0x00000000>,
			    <0x0418 0x00000000>,
			    <0x041c 0x00000000>,
			    <0x0420 0x00000000>,
			    <0x0424 0x00000000>,
			    <0x0428 0x00000000>,
			    <0x042c 0x00000000>,
			    <0x0430 0x00000000>,
			    <0x0434 0x00000000>,
			    <0x0438 0x00000000>,
			    <0x043c 0x00000000>,
			    <0x0440 0x00000000>,
			    <0x0444 0x00000000>,
			    <0x0448 0x00000000>,
			    <0x044c 0x00000000>,
			    <0x0450 0x00000000>,
			    <0x0454 0x00000000>,
			    <0x0458 0x00000000>,
			    <0x045c 0x00000000>,
			    <0x0460 0x00000000>,
			    <0x0464 0x00000000>,
			    <0x0468 0x00000000>,
			    <0x046c 0x00000000>,
			    <0x0470 0x00000000>,
			    <0x0474 0x00000000>,
			    <0x0478 0x00000000>,
			    <0x047c 0x00000000>,
			    <0x0480 0x00000000>,
			    <0x0484 0x00000000>,
			    <0x0488 0x00000000>,
			    <0x048c 0x00000000>,
			    <0x0490 0x00000000>,
			    <0x0494 0x00000000>,
			    <0x0498 0x00000000>,
			    <0x049c 0x00000000>,
			    <0x04a0 0x00000000>,
			    <0x04a4 0x00000000>,
			    <0x04a8 0x00000000>,
			    <0x04ac 0x00000000>,
			    <0x04b0 0x00000000>,
			    <0x04b4 0x00000000>,
			    <0x04b8 0x00000000>,
			    <0x04bc 0x00000000>,
			    <0x04c0 0x00000000>,
			    <0x04c4 0x00000000>,
			    <0x04c8 0x00000000>,
			    <0x04cc 0x00000000>,
			    <0x04d0 0x00000000>,
			    <0x04d4 0x00000000>,
			    <0x04d8 0x00000000>,
			    <0x04dc 0x00000000>,
			    <0x04e0 0x00000000>,
			    <0x04e4 0x00000000>,
			    <0x04e8 0x00000000>,
			    <0x04ec 0x00000000>,
			    <0x04f0 0x00000000>,
			    <0x04f4 0x00000000>,
			    <0x04f8 0x00000000>,
			    <0x04fc 0x00000000>,
			    <0x0500 0x00000000>,
			    <0x0504 0x00000000>,
			    <0x0508 0x00000000>,
			    <0x050c 0x00000000>,
			    <0x0510 0x00000000>,
			    <0x0514 0x00000000>,
			    <0x0518 0x00000000>,
			    <0x051c 0x00000000>,
			    <0x0520 0x00000000>,
			    <0x0524 0x00000000>,
			    <0x0528 0x00000000>,
			    <0x052c 0x00000000>,
			    <0x0530 0x00000000>,
			    <0x0534 0x00000000>,
			    <0x0538 0x00000000>,
			    <0x053c 0x00000000>,
			    <0x0540 0x00000000>,
			    <0x0544 0x00000000>,
			    <0x0548 0x00000000>,
			    <0x054c 0x00000000>,
			    <0x0550 0x00000000>,
			    <0x0554 0x00000000>,
			    <0x0558 0x00000000>,
			    <0x055c 0x00000000>,
			    <0x0560 0x00000000>,
			    <0x0564 0x00000000>,
			    <0x0568 0x00000000>,
			    <0x056c 0x00000000>,
			    <0x0570 0x00000000>,
			    <0x0574 0x00000000>,
			    <0x0578 0x00000000>,
			    <0x057c 0x00000000>,
			    <0x0580 0x00000000>,
			    <0x0584 0x00000000>,
			    <0x0588 0x00000000>,
			    <0x058c 0x00000000>,
			    <0x0590 0x00000000>,
			    <0x0594 0x00000000>,
			    <0x0598 0x00000000>,
			    <0x059c 0x00000000>,
			    <0x05a0 0x00000000>,
			    <0x05a4 0x00000000>,
			    <0x05a8 0x00000000>,
			    <0x05ac 0x00000000>,
			    <0x05b0 0x00000000>,
			    <0x05b4 0x00000000>,
			    <0x05b8 0x00000000>,
			    <0x05bc 0x00000000>,
			    <0x05c0 0x00000000>,
			    <0x05c4 0x00000000>,
			    <0x05c8 0x00000000>,
			    <0x05cc 0x00000000>,
			    <0x05d0 0x00000000>,
			    <0x05d4 0x00000000>,
			    <0x05d8 0x00000000>,
			    <0x05dc 0x00000000>,
			    <0x05e0 0x00000000>,
			    <0x05e4 0x00000000>,
			    <0x05e8 0x00000000>,
			    <0x05ec 0x00000000>,
			    <0x05f0 0x00000000>,
			    <0x05f4 0x00000000>,
			    <0x05f8 0x00000000>,
			    <0x05fc 0x00000000>,
			    <0x0600 0x00000000>,
			    <0x0604 0x00000000>,
			    <0x0608 0x00000000>,
			    <0x060c 0x00000000>,
			    <0x0610 0x00000000>,
			    <0x0614 0x00000000>,
			    <0x0618 0x00000000>,
			    <0x061c 0x00000000>,
			    <0x0620 0x00000000>,
			    <0x0624 0x00000000>,
			    <0x0628 0x00000000>,
			    <0x062c 0x00000000>,
			    <0x0630 0x00000000>,
			    <0x0634 0x00000000>,
			    <0x0638 0x00000000>,
			    <0x063c 0x00000000>,
			    <0x0640 0x00000000>,
			    <0x0644 0x00000000>,
			    <0x0648 0x00000000>,
			    <0x064c 0x00000000>,
			    <0x0650 0x00000000>,
			    <0x0654 0x00000000>,
			    <0x0658 0x00000000>,
			    <0x065c 0x00000000>,
			    <0x0660 0x00000000>,
			    <0x0664 0x00000000>,
			    <0x0668 0x00000000>,
			    <0x066c 0x00000000>,
			    <0x0670 0x00000000>,
			    <0x0674 0x00000000>,
			    <0x0678 0x00000000>,
			    <0x067c 0x00000000>,
			    <0x0680 0x00000000>,
			    <0x0684 0x00000000>,
			    <0x0688 0x00000000>,
			    <0x068c 0x00000000>,
			    <0x0690 0x00000000>,
			    <0x0694 0x00000000>,
			    <0x0698 0x00000000>,
			    <0x069c 0x00000000>,
			    <0x06a0 0x00000000>,
			    <0x06a4 0x00000000>,
			    <0x06a8 0x00000000>,
			    <0x06ac 0x00000000>,
			    <0x06b0 0x00000000>,
			    <0x06b4 0x00000000>,
			    <0x06b8 0x00000000>,
			    <0x06bc 0x00000000>,
			    <0x06c0 0x00000000>,
			    <0x06c4 0x00000000>,
			    <0x06c8 0x00000000>,
			    <0x06cc 0x00000000>,
			    <0x06d0 0x00000000>,
			    <0x06d4 0x00000000>,
			    <0x06d8 0x00000000>,
			    <0x06dc 0x00000000>,
			    <0x06e0 0x00000000>,
			    <0x06e4 0x00000000>,
			    <0x06e8 0x00000000>,
			    <0x06ec 0x00000000>,
			    <0x06f0 0x00000000>,
			    <0x06f4 0x00000000>,
			    <0x06f8 0x00000000>,
			    <0x06fc 0x00000000>,
			    <0x0700 0x00000000>,
			    <0x0704 0x00000000>,
			    <0x0708 0x00000000>,
			    <0x070c 0x00000000>,
			    <0x0710 0x00000000>,
			    <0x0714 0x00000000>,
			    <0x0718 0x00000000>,
			    <0x071c 0x00000000>,
			    <0x0720 0x00000000>,
			    <0x0724 0x00000000>,
			    <0x0728 0x00000000>,
			    <0x072c 0x00000000>,
			    <0x0730 0x00000000>,
			    <0x0734 0x00000000>,
			    <0x0738 0x00000000>,
			    <0x073c 0x00000000>,
			    <0x0740 0x00000000>,
			    <0x0744 0x00000000>,
			    <0x0748 0x00000000>,
			    <0x074c 0x00000000>,
			    <0x0750 0x00000000>,
			    <0x0754 0x00000000>,
			    <0x0758 0x00000000>,
			    <0x075c 0x00000000>,
			    <0x0760 0x00000000>,
			    <0x0764 0x00000000>,
			    <0x0768 0x00000000>,
			    <0x076c 0x00000000>,
			    <0x0770 0x00000000>,
			    <0x0774 0x00000000>,
			    <0x0778 0x00000000>,
			    <0x077c 0x00000000>,
			    <0x0780 0x00000000>,
			    <0x0784 0x00000000>,
			    <0x0788 0x00000000>,
			    <0x078c 0x00000000>,
			    <0x0790 0x00000000>,
			    <0x0794 0x00000000>,
			    <0x0798 0x00000000>,
			    <0x079c 0x00000000>,
			    <0x07a0 0x00000000>,
			    <0x07a4 0x00000000>,
			    <0x07a8 0x00000000>,
			    <0x07ac 0x00000000>,
			    <0x07b0 0x00000000>,
			    <0x07b4 0x00000000>,
			    <0x07b8 0x00000000>,
			    <0x07bc 0x00000000>,
			    <0x07c0 0x00000000>,
			    <0x07c4 0x00000000>,
			    <0x07c8 0x00000000>,
			    <0x07cc 0x00000000>,
			    <0x07d0 0x00000000>,
			    <0x07d4 0x00000000>,
			    <0x07d8 0x00000000>,
			    <0x07dc 0x00000000>,
			    <0x07e0 0x00000000>,
			    <0x07e4 0x00000000>,
			    <0x07e8 0x00000000>,
			    <0x07ec 0x00000000>,
			    <0x07f0 0x00000000>,
			    <0x07f4 0x00000000>,
			    <0x07f8 0x00000000>,
			    <0x07fc 0x00000000>,
			    <0x0800 0x00000000>,
			    <0x0804 0x00000000>,
			    <0x0808 0x00000000>,
			    <0x080c 0x00000000>,
			    <0x0810 0x00000000>,
			    <0x0814 0x00000000>,
			    <0x0818 0x00000000>,
			    <0x081c 0x00000000>,
			    <0x0820 0x00000000>,
			    <0x0824 0x00000000>,
			    <0x0828 0x00000000>,
			    <0x082c 0x00000000>,
			    <0x0830 0x00000000>,
			    <0x0834 0x00000000>,
			    <0x0838 0x00000000>,
			    <0x083c 0x00000000>,
			    <0x0840 0x00000000>,
			    <0x0844 0x00000000>,
			    <0x0848 0x00000000>,
			    <0x084c 0x00000000>,
			    <0x0850 0x00000000>,
			    <0x0854 0x00000000>,
			    <0x0858 0x00000000>,
			    <0x085c 0x00000000>,
			    <0x0860 0x00000000>,
			    <0x0864 0x00000000>,
			    <0x0868 0x00000000>,
			    <0x086c 0x00000000>,
			    <0x0870 0x00000000>,
			    <0x0874 0x00000000>,
			    <0x0878 0x00000000>,
			    <0x087c 0x00000000>,
			    <0x0880 0x00000000>,
			    <0x0884 0x00000000>,
			    <0x0888 0x00000000>,
			    <0x088c 0x00000000>,
			    <0x0890 0x00000000>,
			    <0x0894 0x00000000>,
			    <0x0898 0x00000000>,
			    <0x089c 0x00000000>,
			    <0x08a0 0x08b12400>,
			    <0x08a4 0x1113c4c6>,
			    <0x08a8 0x16853530>,
			    <0x08ac 0x1b166d82>,
			    <0x08b0 0x1ed76dc7>,
			    <0x08b4 0x21b835fe>,
			    <0x08b8 0x2448da29>,
			    <0x08bc 0x26d97e52>,
			    <0x08c0 0x293a1e7a>,
			    <0x08c4 0x2b9ab2a0>,
			    <0x08c8 0x2ddb46c5>,
			    <0x08cc 0x2ffbd2e8>,
			    <0x08d0 0x31dc4f09>,
			    <0x08d4 0x33acc326>,
			    <0x08d8 0x356d3743>,
			    <0x08dc 0x372da35f>,
			    <0x08e0 0x38ce137b>,
			    <0x08e4 0x3a6e7b95>,
			    <0x08e8 0x3bfedfaf>,
			    <0x08ec 0x3d8f43c8>,
			    <0x08f0 0x3effa3e0>,
			    <0x08f4 0x000ffff7>,
			    <0x08f8 0x00000000>,
			    <0x08fc 0x00000000>,
			    <0x0900 0x00000001>,
			    <0x0904 0x00000000>,
			    <0x0908 0x00000000>,
			    <0x090c 0x00000000>,
			    <0x0910 0x00000000>,
			    <0x0914 0x000a0028>,
			    <0x0918 0x80000000>,
			    <0x091c 0x00000000>,
			    <0x0920 0xf8888888>,
			    <0x0924 0x485f7880>,
			    <0x0928 0x2428303a>,
			    <0x092c 0x20202020>,
			    <0x0930 0x20202020>,
			    <0x0934 0x00a00020>,
			    <0x0938 0x00014008>,
			    <0x093c 0x122347ff>,
			    <0x0940 0x00000111>,
			    <0x0944 0x40081007>,
			    <0x0948 0x00408003>,
			    <0x094c 0x00cc00cc>,
			    <0x0950 0xa80080e6>,
			    <0x0954 0x00800080>,
			    <0x0958 0x00010080>,
			    <0x095c 0x00000100>,
			    <0x0960 0xffffe0c0>,
			    <0x0964 0x00000000>,
			    <0x0968 0x00000000>,
			    <0x096c 0x00000000>,
			    <0x0970 0x00000000>,
			    <0x0974 0x000002a0>,
			    <0x0978 0x00000000>,
			    <0x097c 0x00000000>,
			    <0x0980 0x00000000>,
			    <0x0984 0x00000000>,
			    <0x0988 0x00000000>,
			    <0x098c 0x00000000>,
			    <0x0990 0x00000000>,
			    <0x0994 0x00000000>,
			    <0x0998 0x00000000>,
			    <0x099c 0x00000000>,
			    <0x09a0 0x00000000>,
			    <0x09a4 0x00000000>,
			    <0x09a8 0x00000000>,
			    <0x09ac 0x00000000>,
			    <0x09b0 0x00000000>,
			    <0x09b4 0x00000000>,
			    <0x09b8 0x00000000>,
			    <0x09bc 0x00000000>,
			    <0x09c0 0x00000000>,
			    <0x09c4 0x00000000>,
			    <0x09c8 0x00000000>,
			    <0x09cc 0x00000000>,
			    <0x09d0 0x00000000>,
			    <0x09d4 0x00000000>,
			    <0x09d8 0x00000000>,
			    <0x09dc 0x00000000>,
			    <0x09e0 0x00000000>,
			    <0x09e4 0x00000000>,
			    <0x09e8 0x00000000>,
			    <0x09ec 0x00000000>,
			    <0x09f0 0x00000000>,
			    <0x09f4 0x00000000>,
			    <0x09f8 0x00000000>,
			    <0x09fc 0x00000000>,
			    <0x0a00 0x00000000>,
			    <0x0a04 0x00000000>,
			    <0x0a08 0x00000000>,
			    <0x0a0c 0x00000000>,
			    <0x0a10 0x00000000>,
			    <0x0a14 0x00000000>,
			    <0x0a18 0x00000000>,
			    <0x0a1c 0x00000000>,
			    <0x0a20 0x00000000>,
			    <0x0a24 0x00000000>,
			    <0x0a28 0x00000000>,
			    <0x0a2c 0x00000000>,
			    <0x0a30 0x00000000>,
			    <0x0a34 0x00000000>,
			    <0x0a38 0x00000000>,
			    <0x0a3c 0x00000000>,
			    <0x0a40 0x00000000>,
			    <0x0a44 0x00000000>,
			    <0x0a48 0x00000000>,
			    <0x0a4c 0x00000000>,
			    <0x0a50 0x00000000>,
			    <0x0a54 0x00000000>,
			    <0x0a58 0x00000000>,
			    <0x0a5c 0x00000000>,
			    <0x0a60 0x00000000>,
			    <0x0a64 0x00000000>,
			    <0x0a68 0x00000000>,
			    <0x0a6c 0x00000000>,
			    <0x0a70 0x00000000>,
			    <0x0a74 0x00000000>,
			    <0x0a78 0x00000000>,
			    <0x0a7c 0x00000000>,
			    <0x0a80 0x00000000>,
			    <0x0a84 0x00000000>,
			    <0x0a88 0x00000000>,
			    <0x0a8c 0x00000000>,
			    <0x0a90 0x00000000>,
			    <0x0a94 0x00000000>,
			    <0x0a98 0x00000000>,
			    <0x0a9c 0x00000000>,
			    <0x0aa0 0x00000000>,
			    <0x0aa4 0x00000000>,
			    <0x0aa8 0x00000000>,
			    <0x0aac 0x00000000>,
			    <0x0ab0 0x00000000>,
			    <0x0ab4 0x00000000>,
			    <0x0ab8 0x00000000>,
			    <0x0abc 0x00000000>,
			    <0x0ac0 0x00000000>,
			    <0x0ac4 0x00000000>,
			    <0x0ac8 0x00000000>,
			    <0x0acc 0x00000000>,
			    <0x0ad0 0x00000000>,
			    <0x0ad4 0x00000000>,
			    <0x0ad8 0x00000000>,
			    <0x0adc 0x00000000>,
			    <0x0ae0 0x00000000>,
			    <0x0ae4 0x00000000>,
			    <0x0ae8 0x00000000>,
			    <0x0aec 0x00000000>,
			    <0x0af0 0x00000000>,
			    <0x0af4 0x00000000>,
			    <0x0af8 0x00000000>,
			    <0x0afc 0x00000000>,
			    <0x0b00 0x00000000>,
			    <0x0b04 0x00000000>,
			    <0x0b08 0x00000000>,
			    <0x0b0c 0x00000000>,
			    <0x0b10 0x00000000>,
			    <0x0b14 0x00000000>,
			    <0x0b18 0x00000000>,
			    <0x0b1c 0x00000000>,
			    <0x0b20 0x00000000>,
			    <0x0b24 0x00000000>,
			    <0x0b28 0x00000000>,
			    <0x0b2c 0x00000000>,
			    <0x0b30 0x00000000>,
			    <0x0b34 0x00000000>,
			    <0x0b38 0x00000000>,
			    <0x0b3c 0x00000000>,
			    <0x0b40 0x00000000>,
			    <0x0b44 0x00000000>,
			    <0x0b48 0x00000000>,
			    <0x0b4c 0x00000000>,
			    <0x0b50 0x00000000>,
			    <0x0b54 0x00000000>,
			    <0x0b58 0x00000000>,
			    <0x0b5c 0x00000000>,
			    <0x0b60 0x00000000>,
			    <0x0b64 0x00000000>,
			    <0x0b68 0x00000000>,
			    <0x0b6c 0x00000000>,
			    <0x0b70 0x00000000>,
			    <0x0b74 0x00000000>,
			    <0x0b78 0x00000000>,
			    <0x0b7c 0x00000000>,
			    <0x0b80 0x00000000>,
			    <0x0b84 0x00000000>,
			    <0x0b88 0x00000000>,
			    <0x0b8c 0x00000000>,
			    <0x0b90 0x00000000>,
			    <0x0b94 0x00000000>,
			    <0x0b98 0x00000000>,
			    <0x0b9c 0x00000000>,
			    <0x0ba0 0x00000000>,
			    <0x0ba4 0x00000000>,
			    <0x0ba8 0x00000000>,
			    <0x0bac 0x00000000>,
			    <0x0bb0 0x00000000>,
			    <0x0bb4 0x00000000>,
			    <0x0bb8 0x00000000>,
			    <0x0bbc 0x00000000>,
			    <0x0bc0 0x00000000>,
			    <0x0bc4 0x00000000>,
			    <0x0bc8 0x00000000>,
			    <0x0bcc 0x00000000>,
			    <0x0bd0 0x00000000>,
			    <0x0bd4 0x00000000>,
			    <0x0bd8 0x00000000>,
			    <0x0bdc 0x00000000>,
			    <0x0be0 0x00000000>,
			    <0x0be4 0x00000000>,
			    <0x0be8 0x00000000>,
			    <0x0bec 0x00000000>,
			    <0x0bf0 0x00000000>,
			    <0x0bf4 0x00000000>,
			    <0x0bf8 0x00000000>,
			    <0x0bfc 0x00000000>,
			    <0x0c00 0x00000000>,
			    <0x0c04 0x00000000>,
			    <0x0c08 0x00000000>,
			    <0x0c0c 0x00000000>,
			    <0x0c10 0x00000000>,
			    <0x0c14 0x00000000>,
			    <0x0c18 0x00000000>,
			    <0x0c1c 0x00000000>,
			    <0x0c20 0x00000000>,
			    <0x0c24 0x00000000>,
			    <0x0c28 0x00000000>,
			    <0x0c2c 0x00000000>,
			    <0x0c30 0x00000000>,
			    <0x0c34 0x00000000>,
			    <0x0c38 0x00000000>,
			    <0x0c3c 0x00000000>,
			    <0x0c40 0x00000000>,
			    <0x0c44 0x00000000>,
			    <0x0c48 0x00000000>,
			    <0x0c4c 0x00000000>,
			    <0x0c50 0x00000000>,
			    <0x0c54 0x00000000>,
			    <0x0c58 0x00000000>,
			    <0x0c5c 0x00000000>,
			    <0x0c60 0x00000000>,
			    <0x0c64 0x00000000>,
			    <0x0c68 0x00000000>,
			    <0x0c6c 0x00000000>,
			    <0x0c70 0x00000000>,
			    <0x0c74 0x00000000>,
			    <0x0c78 0x00000000>,
			    <0x0c7c 0x00000000>,
			    <0x0c80 0x00000000>,
			    <0x0c84 0x00000000>,
			    <0x0c88 0x00000000>,
			    <0x0c8c 0x00000000>,
			    <0x0c90 0x00000000>,
			    <0x0c94 0x00000000>,
			    <0x0c98 0x00000000>,
			    <0x0c9c 0x00000000>,
			    <0x0ca0 0x00000000>,
			    <0x0ca4 0x00000000>,
			    <0x0ca8 0x00000000>,
			    <0x0cac 0x00000000>,
			    <0x0cb0 0x00000000>,
			    <0x0cb4 0x00000000>,
			    <0x0cb8 0x00000000>,
			    <0x0cbc 0x00000000>,
			    <0x0cc0 0x00000000>,
			    <0x0cc4 0x00000000>,
			    <0x0cc8 0x00000000>,
			    <0x0ccc 0x00000000>,
			    <0x0cd0 0x00000000>,
			    <0x0cd4 0x00000000>,
			    <0x0cd8 0x00000000>,
			    <0x0cdc 0x00000000>,
			    <0x0ce0 0x00000000>,
			    <0x0ce4 0x00000000>,
			    <0x0ce8 0x00000000>,
			    <0x0cec 0x00000000>,
			    <0x0cf0 0x00000000>,
			    <0x0cf4 0x00000000>,
			    <0x0cf8 0x00000000>,
			    <0x0cfc 0x00000000>,
			    <0x0d00 0x00000000>,
			    <0x0d04 0x00000000>,
			    <0x0d08 0x00000000>,
			    <0x0d0c 0x00000000>,
			    <0x0d10 0x00000000>,
			    <0x0d14 0x00000000>,
			    <0x0d18 0x00000000>,
			    <0x0d1c 0x00000000>,
			    <0x0d20 0x00000000>,
			    <0x0d24 0x00000000>,
			    <0x0d28 0x00000000>,
			    <0x0d2c 0x00000000>,
			    <0x0d30 0x00000000>,
			    <0x0d34 0x00000000>,
			    <0x0d38 0x00000000>,
			    <0x0d3c 0x00000000>,
			    <0x0d40 0x00000000>,
			    <0x0d44 0x00000000>,
			    <0x0d48 0x00000000>,
			    <0x0d4c 0x00000000>,
			    <0x0d50 0x00000000>,
			    <0x0d54 0x00000000>,
			    <0x0d58 0x00000000>,
			    <0x0d5c 0x00000000>,
			    <0x0d60 0x00000000>,
			    <0x0d64 0x00000000>,
			    <0x0d68 0x00000000>,
			    <0x0d6c 0x00000000>,
			    <0x0d70 0x00000000>,
			    <0x0d74 0x00000000>,
			    <0x0d78 0x00000000>,
			    <0x0d7c 0x00000000>,
			    <0x0d80 0x00000000>,
			    <0x0d84 0x00000000>,
			    <0x0d88 0x00000000>,
			    <0x0d8c 0x00000000>,
			    <0x0d90 0x00000000>,
			    <0x0d94 0x00000000>,
			    <0x0d98 0x00000000>,
			    <0x0d9c 0x00000000>,
			    <0x0da0 0x00000000>,
			    <0x0da4 0x00000000>,
			    <0x0da8 0x00000000>,
			    <0x0dac 0x00000000>,
			    <0x0db0 0x00000000>,
			    <0x0db4 0x00000000>,
			    <0x0db8 0x00000000>,
			    <0x0dbc 0x00000000>,
			    <0x0dc0 0x00000000>,
			    <0x0dc4 0x00000000>,
			    <0x0dc8 0x00000000>,
			    <0x0dcc 0x00000000>,
			    <0x0dd0 0x00000000>,
			    <0x0dd4 0x00000000>,
			    <0x0dd8 0x00000000>,
			    <0x0ddc 0x00000000>,
			    <0x0de0 0x00000000>,
			    <0x0de4 0x00000000>,
			    <0x0de8 0x00000000>,
			    <0x0dec 0x00000000>,
			    <0x0df0 0x00000000>,
			    <0x0df4 0x00000000>,
			    <0x0df8 0x00000000>,
			    <0x0dfc 0x00000000>,
			    <0x0e00 0x00000000>,
			    <0x0e04 0x00000000>,
			    <0x0e08 0x00000000>,
			    <0x0e0c 0x00000000>,
			    <0x0e10 0x00000000>,
			    <0x0e14 0x00000000>,
			    <0x0e18 0x00000000>,
			    <0x0e1c 0x00000000>,
			    <0x0e20 0x00000000>,
			    <0x0e24 0x00000000>,
			    <0x0e28 0x00000000>,
			    <0x0e2c 0x00000000>,
			    <0x0e30 0x00000000>,
			    <0x0e34 0x00000000>,
			    <0x0e38 0x00000000>,
			    <0x0e3c 0x00000000>,
			    <0x0e40 0x00000000>,
			    <0x0e44 0x00000000>,
			    <0x0e48 0x00000000>,
			    <0x0e4c 0x00000000>,
			    <0x0e50 0x00000000>,
			    <0x0e54 0x00000000>,
			    <0x0e58 0x00000000>,
			    <0x0e5c 0x00000000>,
			    <0x0e60 0x00000000>,
			    <0x0e64 0x00000000>,
			    <0x0e68 0x00000000>,
			    <0x0e6c 0x00000000>,
			    <0x0e70 0x00000000>,
			    <0x0e74 0x00000000>,
			    <0x0e78 0x00000000>,
			    <0x0e7c 0x00000000>,
			    <0x0e80 0x00000000>,
			    <0x0e84 0x00000000>,
			    <0x0e88 0x00000000>,
			    <0x0e8c 0x00000000>,
			    <0x0e90 0x00000000>,
			    <0x0e94 0x00000000>,
			    <0x0e98 0x00000000>,
			    <0x0e9c 0x00000000>,
			    <0x0ea0 0x00000000>,
			    <0x0ea4 0x00000000>,
			    <0x0ea8 0x00000000>,
			    <0x0eac 0x00000000>,
			    <0x0eb0 0x00000000>,
			    <0x0eb4 0x00000000>,
			    <0x0eb8 0x00000000>,
			    <0x0ebc 0x00000000>,
			    <0x0ec0 0x00000000>,
			    <0x0ec4 0x00000000>,
			    <0x0ec8 0x00000000>,
			    <0x0ecc 0x00000000>,
			    <0x0ed0 0x00000000>,
			    <0x0ed4 0x00000000>,
			    <0x0ed8 0x00000000>,
			    <0x0edc 0x00000000>,
			    <0x0ee0 0x00000000>,
			    <0x0ee4 0x00000000>,
			    <0x0ee8 0x00000000>,
			    <0x0eec 0x00000000>,
			    <0x0ef0 0x00000000>,
			    <0x0ef4 0x00000000>,
			    <0x0ef8 0x00000000>,
			    <0x0efc 0x00000000>,
			    <0x0f00 0x00000000>,
			    <0x0f04 0x00000000>,
			    <0x0f08 0x00000000>,
			    <0x0f0c 0x00000000>,
			    <0x0f10 0x00000000>,
			    <0x0f14 0x00000000>,
			    <0x0f18 0x00000000>,
			    <0x0f1c 0x00000000>,
			    <0x0f20 0x00000000>,
			    <0x0f24 0x00000000>,
			    <0x0f28 0x00000000>,
			    <0x0f2c 0x00000000>,
			    <0x0f30 0x00000000>,
			    <0x0f34 0x00000000>,
			    <0x0f38 0x00000000>,
			    <0x0f3c 0x00000000>,
			    <0x0f40 0x00000000>,
			    <0x0f44 0x00000000>,
			    <0x0f48 0x00000000>,
			    <0x0f4c 0x00000000>,
			    <0x0f50 0x00000000>,
			    <0x0f54 0x00000000>,
			    <0x0f58 0x00000000>,
			    <0x0f5c 0x00000000>,
			    <0x0f60 0x00000000>,
			    <0x0f64 0x00000000>,
			    <0x0f68 0x00000000>,
			    <0x0f6c 0x00000000>,
			    <0x0f70 0x00000000>,
			    <0x0f74 0x00000000>,
			    <0x0f78 0x00000000>,
			    <0x0f7c 0x00000000>,
			    <0x0f80 0x00000000>,
			    <0x0f84 0x00000000>,
			    <0x0f88 0x00000000>,
			    <0x0f8c 0x00000000>,
			    <0x0f90 0x00000000>,
			    <0x0f94 0x00000000>,
			    <0x0f98 0x00000000>,
			    <0x0f9c 0x00000000>,
			    <0x0fa0 0x00000000>,
			    <0x0fa4 0x00000000>,
			    <0x0fa8 0x00000000>,
			    <0x0fac 0x00000000>,
			    <0x0fb0 0x00000000>,
			    <0x0fb4 0x00000000>,
			    <0x0fb8 0x00000000>,
			    <0x0fbc 0x00000000>,
			    <0x0fc0 0x00000000>,
			    <0x0fc4 0x00000000>,
			    <0x0fc8 0x00000000>,
			    <0x0fcc 0x00000000>,
			    <0x0fd0 0x00000000>,
			    <0x0fd4 0x00000000>,
			    <0x0fd8 0x00000000>,
			    <0x0fdc 0x00000000>,
			    <0x0fe0 0x00000000>,
			    <0x0fe4 0x00000000>,
			    <0x0fe8 0x00000000>,
			    <0x0fec 0x00000000>,
			    <0x0ff0 0x00000000>,
			    <0x0ff4 0x00000000>,
			    <0x0ff8 0x00000000>,
			    <0x0ffc 0x00000000>,
			    <0x1000 0x00000000>,
			    <0x1004 0x00000000>,
			    <0x1008 0x00000000>,
			    <0x100c 0x00000000>,
			    <0x1010 0x00000000>,
			    <0x1014 0x00000000>,
			    <0x1018 0x00000000>,
			    <0x101c 0x00000000>,
			    <0x1020 0x00000000>,
			    <0x1024 0x00000000>,
			    <0x1028 0x00000000>,
			    <0x102c 0x00000000>,
			    <0x1030 0x00000000>,
			    <0x1034 0x00000000>,
			    <0x1038 0x00000000>,
			    <0x103c 0x00000000>,
			    <0x1040 0x00000000>,
			    <0x1044 0x00000000>,
			    <0x1048 0x00000000>,
			    <0x104c 0x00000000>,
			    <0x1050 0x00000000>,
			    <0x1054 0x00000000>,
			    <0x1058 0x00000000>,
			    <0x105c 0x00000000>,
			    <0x1060 0x00000000>,
			    <0x1064 0x00000000>,
			    <0x1068 0x00000000>,
			    <0x106c 0x00000000>,
			    <0x1070 0x00000000>,
			    <0x1074 0x00000000>,
			    <0x1078 0x00000000>,
			    <0x107c 0x00000000>,
			    <0x1080 0x00000000>,
			    <0x1084 0x00000000>,
			    <0x1088 0x00000000>,
			    <0x108c 0x00000000>,
			    <0x1090 0x00000000>,
			    <0x1094 0x00000000>,
			    <0x1098 0x00000000>,
			    <0x109c 0x00000000>,
			    <0x10a0 0x00000000>,
			    <0x10a4 0x00000000>,
			    <0x10a8 0x00000000>,
			    <0x10ac 0x00000000>,
			    <0x10b0 0x00000000>,
			    <0x10b4 0x00000000>,
			    <0x10b8 0x00000000>,
			    <0x10bc 0x00000000>,
			    <0x10c0 0x00000000>,
			    <0x10c4 0x00000000>,
			    <0x10c8 0x00000000>,
			    <0x10cc 0x00000000>,
			    <0x10d0 0x00000000>,
			    <0x10d4 0x00000000>,
			    <0x10d8 0x00000000>,
			    <0x10dc 0x00000000>,
			    <0x10e0 0x00000000>,
			    <0x10e4 0x00000000>,
			    <0x10e8 0x00000000>,
			    <0x10ec 0x00000000>,
			    <0x10f0 0x00000000>,
			    <0x10f4 0x00000000>,
			    <0x10f8 0x00000000>,
			    <0x10fc 0x00000000>,
			    <0x1100 0x00000000>,
			    <0x1104 0x00000000>,
			    <0x1108 0x00000000>,
			    <0x110c 0x00000000>,
			    <0x1110 0x00000000>,
			    <0x1114 0x00000000>,
			    <0x1118 0x00000000>,
			    <0x111c 0x00000000>,
			    <0x1120 0x00000000>,
			    <0x1124 0x00000000>,
			    <0x1128 0x00000000>,
			    <0x112c 0x00000000>,
			    <0x1130 0x00000000>,
			    <0x1134 0x00000000>,
			    <0x1138 0x00000000>,
			    <0x113c 0x00000000>,
			    <0x1140 0x00000000>,
			    <0x1144 0x00000000>,
			    <0x1148 0x00000000>,
			    <0x114c 0x00000000>,
			    <0x1150 0x00000000>,
			    <0x1154 0x00000000>,
			    <0x1158 0x00000000>,
			    <0x115c 0x00000000>,
			    <0x1160 0x00000000>,
			    <0x1164 0x00000000>,
			    <0x1168 0x00000000>,
			    <0x116c 0x00000000>,
			    <0x1170 0x00000000>,
			    <0x1174 0x00000000>,
			    <0x1178 0x00000000>,
			    <0x117c 0x00000000>,
			    <0x1180 0x00000000>,
			    <0x1184 0x00000000>,
			    <0x1188 0x00000000>,
			    <0x118c 0x00000000>,
			    <0x1190 0x00000000>,
			    <0x1194 0x00000000>,
			    <0x1198 0x00000000>,
			    <0x119c 0x00000000>,
			    <0x11a0 0x00000000>,
			    <0x11a4 0x00000000>,
			    <0x11a8 0x00000000>,
			    <0x11ac 0x00000000>,
			    <0x11b0 0x00000000>,
			    <0x11b4 0x00000000>,
			    <0x11b8 0x00000000>,
			    <0x11bc 0x00000000>,
			    <0x11c0 0x00000000>,
			    <0x11c4 0x00000000>,
			    <0x11c8 0x00000000>,
			    <0x11cc 0x00000000>,
			    <0x11d0 0x00000000>,
			    <0x11d4 0x00000000>,
			    <0x11d8 0x00000000>,
			    <0x11dc 0x00000000>,
			    <0x11e0 0x00000000>,
			    <0x11e4 0x00000000>,
			    <0x11e8 0x00000000>,
			    <0x11ec 0x00000000>,
			    <0x11f0 0x00000000>,
			    <0x11f4 0x00000000>,
			    <0x11f8 0x00000000>,
			    <0x11fc 0x00000000>,
			    <0x1200 0x00000000>,
			    <0x1204 0x00000000>,
			    <0x1208 0x00000000>,
			    <0x120c 0x00000000>,
			    <0x1210 0x00000000>,
			    <0x1214 0x00000000>,
			    <0x1218 0x00000000>,
			    <0x121c 0x00000000>,
			    <0x1220 0x00000000>,
			    <0x1224 0x00000000>,
			    <0x1228 0x00000000>,
			    <0x122c 0x00000000>,
			    <0x1230 0x00000000>,
			    <0x1234 0x00000000>,
			    <0x1238 0x00000000>,
			    <0x123c 0x00000000>,
			    <0x1240 0x00000000>,
			    <0x1244 0x00000000>,
			    <0x1248 0x00000000>,
			    <0x124c 0x00000000>,
			    <0x1250 0x00000000>,
			    <0x1254 0x00000000>,
			    <0x1258 0x00000000>,
			    <0x125c 0x00000000>,
			    <0x1260 0x00000000>,
			    <0x1264 0x00000000>,
			    <0x1268 0x00000000>,
			    <0x126c 0x00000000>,
			    <0x1270 0x00000000>,
			    <0x1274 0x00000000>,
			    <0x1278 0x00000000>,
			    <0x127c 0x00000000>,
			    <0x1280 0x00000000>,
			    <0x1284 0x00000000>,
			    <0x1288 0x00000000>,
			    <0x128c 0x00000000>,
			    <0x1290 0x00000000>,
			    <0x1294 0x00000000>,
			    <0x1298 0x00000000>,
			    <0x129c 0x00000000>,
			    <0x12a0 0x00000000>,
			    <0x12a4 0x00000000>,
			    <0x12a8 0x00000000>,
			    <0x12ac 0x00000000>,
			    <0x12b0 0x00000000>,
			    <0x12b4 0x00000000>,
			    <0x12b8 0x00000000>,
			    <0x12bc 0x00000000>,
			    <0x12c0 0x00000000>,
			    <0x12c4 0x00000000>,
			    <0x12c8 0x00000000>,
			    <0x12cc 0x00000000>,
			    <0x12d0 0x00000000>,
			    <0x12d4 0x00000000>,
			    <0x12d8 0x00000000>,
			    <0x12dc 0x00000000>,
			    <0x12e0 0x00000000>,
			    <0x12e4 0x00000000>,
			    <0x12e8 0x00000000>,
			    <0x12ec 0x00000000>,
			    <0x12f0 0x00000000>,
			    <0x12f4 0x00000000>,
			    <0x12f8 0x00000000>,
			    <0x12fc 0x00000000>,
			    <0x1300 0x00000000>,
			    <0x1304 0x00000000>,
			    <0x1308 0x00000000>,
			    <0x130c 0x00000000>,
			    <0x1310 0x00000000>,
			    <0x1314 0x00000000>,
			    <0x1318 0x00000000>,
			    <0x131c 0x00000000>,
			    <0x1320 0x00000000>,
			    <0x1324 0x00000000>,
			    <0x1328 0x00000000>,
			    <0x132c 0x00000000>,
			    <0x1330 0x00000000>,
			    <0x1334 0x00000000>,
			    <0x1338 0x00000000>,
			    <0x133c 0x00000000>,
			    <0x1340 0x00000000>,
			    <0x1344 0x00000000>,
			    <0x1348 0x00000000>,
			    <0x134c 0x00000000>,
			    <0x1350 0x00000000>,
			    <0x1354 0x00000000>,
			    <0x1358 0x00000000>,
			    <0x135c 0x00000000>,
			    <0x1360 0x00000000>,
			    <0x1364 0x00000000>,
			    <0x1368 0x00000000>,
			    <0x136c 0x00000000>,
			    <0x1370 0x00000000>,
			    <0x1374 0x00000000>,
			    <0x1378 0x00000000>,
			    <0x137c 0x00000000>,
			    <0x1380 0x00000000>,
			    <0x1384 0x00000000>,
			    <0x1388 0x00000000>,
			    <0x138c 0x00000000>,
			    <0x1390 0x00000000>,
			    <0x1394 0x00000000>,
			    <0x1398 0x00000000>,
			    <0x139c 0x00000000>,
			    <0x13a0 0x00000000>,
			    <0x13a4 0x00000000>,
			    <0x13a8 0x00000000>,
			    <0x13ac 0x00000000>,
			    <0x13b0 0x00000000>,
			    <0x13b4 0x00000000>,
			    <0x13b8 0x00000000>,
			    <0x13bc 0x00000000>,
			    <0x13c0 0x00000000>,
			    <0x13c4 0x00000000>,
			    <0x13c8 0x00000000>,
			    <0x13cc 0x00000000>,
			    <0x13d0 0x00000000>,
			    <0x13d4 0x00000000>,
			    <0x13d8 0x00000000>,
			    <0x13dc 0x00000000>,
			    <0x13e0 0x00000000>,
			    <0x13e4 0x00000000>,
			    <0x13e8 0x00000000>,
			    <0x13ec 0x00000000>,
			    <0x13f0 0x00000000>,
			    <0x13f4 0x00000000>,
			    <0x13f8 0x00000000>,
			    <0x13fc 0x00000000>,
			    <0x1400 0x00000000>,
			    <0x1404 0x00000000>,
			    <0x1408 0x00000000>,
			    <0x140c 0x00000000>,
			    <0x1410 0x00000000>,
			    <0x1414 0x00000000>,
			    <0x1418 0x00000000>,
			    <0x141c 0x00000000>,
			    <0x1420 0x00000000>,
			    <0x1424 0x00000000>,
			    <0x1428 0x00000000>,
			    <0x142c 0x00000000>,
			    <0x1430 0x00000000>,
			    <0x1434 0x00000000>,
			    <0x1438 0x00000000>,
			    <0x143c 0x00000000>,
			    <0x1440 0x00000000>,
			    <0x1444 0x00000000>,
			    <0x1448 0x00000000>,
			    <0x144c 0x00000000>,
			    <0x1450 0x00000000>,
			    <0x1454 0x00000000>,
			    <0x1458 0x00000000>,
			    <0x145c 0x00000000>,
			    <0x1460 0x00000000>,
			    <0x1464 0x00000000>,
			    <0x1468 0x00000000>,
			    <0x146c 0x00000000>,
			    <0x1470 0x00000000>,
			    <0x1474 0x00000000>,
			    <0x1478 0x00000000>,
			    <0x147c 0x00000000>,
			    <0x1480 0x00000000>,
			    <0x1484 0x00000000>,
			    <0x1488 0x00000000>,
			    <0x148c 0x00000000>,
			    <0x1490 0x00000000>,
			    <0x1494 0x00000000>,
			    <0x1498 0x00000000>,
			    <0x149c 0x00000000>,
			    <0x14a0 0x00000000>,
			    <0x14a4 0x00000000>,
			    <0x14a8 0x00000000>,
			    <0x14ac 0x00000000>,
			    <0x14b0 0x00000000>,
			    <0x14b4 0x00000000>,
			    <0x14b8 0x00000000>,
			    <0x14bc 0x00000000>,
			    <0x14c0 0x00000000>,
			    <0x14c4 0x00000000>,
			    <0x14c8 0x00000000>,
			    <0x14cc 0x00000000>,
			    <0x14d0 0x00000000>,
			    <0x14d4 0x00000000>,
			    <0x14d8 0x00000000>,
			    <0x14dc 0x00000000>,
			    <0x14e0 0x00000000>,
			    <0x14e4 0x00000000>,
			    <0x14e8 0x00000000>,
			    <0x14ec 0x00000000>,
			    <0x14f0 0x00000000>,
			    <0x14f4 0x00000000>,
			    <0x14f8 0x00000000>,
			    <0x14fc 0x00000000>,
			    <0x1500 0x00000000>,
			    <0x1504 0x00000000>,
			    <0x1508 0x00000000>,
			    <0x150c 0x00000000>,
			    <0x1510 0x00000000>,
			    <0x1514 0x00000000>,
			    <0x1518 0x00000000>,
			    <0x151c 0x00000000>,
			    <0x1520 0x00000000>,
			    <0x1524 0x00000000>,
			    <0x1528 0x00000000>,
			    <0x152c 0x00000000>,
			    <0x1530 0x00000000>,
			    <0x1534 0x00000000>,
			    <0x1538 0x00000000>,
			    <0x153c 0x00000000>,
			    <0x1540 0x00000000>,
			    <0x1544 0x00000000>,
			    <0x1548 0x00000000>,
			    <0x154c 0x00000000>,
			    <0x1550 0x00000000>,
			    <0x1554 0x00000000>,
			    <0x1558 0x00000000>,
			    <0x155c 0x00000000>,
			    <0x1560 0x00000000>,
			    <0x1564 0x00000000>,
			    <0x1568 0x00000000>,
			    <0x156c 0x00000000>,
			    <0x1570 0x00000000>,
			    <0x1574 0x00000000>,
			    <0x1578 0x00000000>,
			    <0x157c 0x00000000>,
			    <0x1580 0x00000000>,
			    <0x1584 0x00000000>,
			    <0x1588 0x00000000>,
			    <0x158c 0x00000000>,
			    <0x1590 0x00000000>,
			    <0x1594 0x00000000>,
			    <0x1598 0x00000000>,
			    <0x159c 0x00000000>,
			    <0x15a0 0x00000000>,
			    <0x15a4 0x00000000>,
			    <0x15a8 0x00000000>,
			    <0x15ac 0x00000000>,
			    <0x15b0 0x00000000>,
			    <0x15b4 0x00000000>,
			    <0x15b8 0x00000000>,
			    <0x15bc 0x00000000>,
			    <0x15c0 0x00000000>,
			    <0x15c4 0x00000000>,
			    <0x15c8 0x00000000>,
			    <0x15cc 0x00000000>,
			    <0x15d0 0x00000000>,
			    <0x15d4 0x00000000>,
			    <0x15d8 0x00000000>,
			    <0x15dc 0x00000000>,
			    <0x15e0 0x00000000>,
			    <0x15e4 0x00000000>,
			    <0x15e8 0x00000000>,
			    <0x15ec 0x00000000>,
			    <0x15f0 0x00000000>,
			    <0x15f4 0x00000000>,
			    <0x15f8 0x00000000>,
			    <0x15fc 0x00000000>,
			    <0x1600 0x00000000>,
			    <0x1604 0x00000000>,
			    <0x1608 0x00000000>,
			    <0x160c 0x00000000>,
			    <0x1610 0x00000000>,
			    <0x1614 0x00000000>,
			    <0x1618 0x00000000>,
			    <0x161c 0x00000000>,
			    <0x1620 0x00000000>,
			    <0x1624 0x00000000>,
			    <0x1628 0x00000000>,
			    <0x162c 0x00000000>,
			    <0x1630 0x00000000>,
			    <0x1634 0x00000000>,
			    <0x1638 0x00000000>,
			    <0x163c 0x00000000>,
			    <0x1640 0x00000000>,
			    <0x1644 0x00000000>,
			    <0x1648 0x00000000>,
			    <0x164c 0x00000000>,
			    <0x1650 0x00000000>,
			    <0x1654 0x00000000>,
			    <0x1658 0x00000000>,
			    <0x165c 0x00000000>,
			    <0x1660 0x00000000>,
			    <0x1664 0x00000000>,
			    <0x1668 0x00000000>,
			    <0x166c 0x00000000>,
			    <0x1670 0x00000000>,
			    <0x1674 0x00000000>,
			    <0x1678 0x00000000>,
			    <0x167c 0x00000000>,
			    <0x1680 0x00000000>,
			    <0x1684 0x00000000>,
			    <0x1688 0x00000000>,
			    <0x168c 0x00000000>,
			    <0x1690 0x00000000>,
			    <0x1694 0x00000000>,
			    <0x1698 0x00000000>,
			    <0x169c 0x00000000>,
			    <0x16a0 0x00000000>,
			    <0x16a4 0x00000000>,
			    <0x16a8 0x00000000>,
			    <0x16ac 0x00000000>,
			    <0x16b0 0x00000000>,
			    <0x16b4 0x00000000>,
			    <0x16b8 0x00000000>,
			    <0x16bc 0x00000000>,
			    <0x16c0 0x00000000>,
			    <0x16c4 0x00000000>,
			    <0x16c8 0x00000000>,
			    <0x16cc 0x00000000>,
			    <0x16d0 0x00000000>,
			    <0x16d4 0x00000000>,
			    <0x16d8 0x00000000>,
			    <0x16dc 0x00000000>,
			    <0x16e0 0x00000000>,
			    <0x16e4 0x00000000>,
			    <0x16e8 0x00000000>,
			    <0x16ec 0x00000000>,
			    <0x16f0 0x00000000>,
			    <0x16f4 0x00000000>,
			    <0x16f8 0x00000000>,
			    <0x16fc 0x00000000>,
			    <0x1700 0x00000000>,
			    <0x1704 0x00000000>,
			    <0x1708 0x00000000>,
			    <0x170c 0x00000000>,
			    <0x1710 0x00000000>,
			    <0x1714 0x00000000>,
			    <0x1718 0x00000000>,
			    <0x171c 0x00000000>,
			    <0x1720 0x00000000>,
			    <0x1724 0x00000000>,
			    <0x1728 0x00000000>,
			    <0x172c 0x00000000>,
			    <0x1730 0x00000000>,
			    <0x1734 0x00000000>,
			    <0x1738 0x00000000>,
			    <0x173c 0x00000000>,
			    <0x1740 0x00000000>,
			    <0x1744 0x00000000>,
			    <0x1748 0x00000000>,
			    <0x174c 0x00000000>,
			    <0x1750 0x00000000>,
			    <0x1754 0x00000000>,
			    <0x1758 0x00000000>,
			    <0x175c 0x00000000>,
			    <0x1760 0x00000000>,
			    <0x1764 0x00000000>,
			    <0x1768 0x00000000>,
			    <0x176c 0x00000000>,
			    <0x1770 0x00000000>,
			    <0x1774 0x00000000>,
			    <0x1778 0x00000000>,
			    <0x177c 0x00000000>,
			    <0x1780 0x00000000>,
			    <0x1784 0x00000000>,
			    <0x1788 0x00000000>,
			    <0x178c 0x00000000>,
			    <0x1790 0x00000000>,
			    <0x1794 0x00000000>,
			    <0x1798 0x00000000>,
			    <0x179c 0x00000000>,
			    <0x17a0 0x00000000>,
			    <0x17a4 0x00000000>,
			    <0x17a8 0x00000000>,
			    <0x17ac 0x00000000>,
			    <0x17b0 0x00000000>,
			    <0x17b4 0x00000000>,
			    <0x17b8 0x00000000>,
			    <0x17bc 0x00000000>,
			    <0x17c0 0x00000000>,
			    <0x17c4 0x00000000>,
			    <0x17c8 0x00000000>,
			    <0x17cc 0x00000000>,
			    <0x17d0 0x00000000>,
			    <0x17d4 0x00000000>,
			    <0x17d8 0x00000000>,
			    <0x17dc 0x00000000>,
			    <0x17e0 0x00000000>,
			    <0x17e4 0x00000000>,
			    <0x17e8 0x00000000>,
			    <0x17ec 0x00000000>,
			    <0x17f0 0x00000000>,
			    <0x17f4 0x00000000>,
			    <0x17f8 0x00000000>,
			    <0x17fc 0x00000000>,
			    <0x1800 0x00000000>,
			    <0x1804 0x00000000>,
			    <0x1808 0x00000000>,
			    <0x180c 0x00000000>,
			    <0x1810 0x00000000>,
			    <0x1814 0x00000000>,
			    <0x1818 0x00000000>,
			    <0x181c 0x00000000>,
			    <0x1820 0x00000000>,
			    <0x1824 0x00000000>,
			    <0x1828 0x00000000>,
			    <0x182c 0x00000000>,
			    <0x1830 0x00000000>,
			    <0x1834 0x00000000>,
			    <0x1838 0x00000000>,
			    <0x183c 0x00000000>,
			    <0x1840 0x00000000>,
			    <0x1844 0x00000000>,
			    <0x1848 0x00000000>,
			    <0x184c 0x00000000>,
			    <0x1850 0x00000000>,
			    <0x1854 0x00000000>,
			    <0x1858 0x00000000>,
			    <0x185c 0x00000000>,
			    <0x1860 0x00000000>,
			    <0x1864 0x00000000>,
			    <0x1868 0x00000000>,
			    <0x186c 0x00000000>,
			    <0x1870 0x00000000>,
			    <0x1874 0x00000000>,
			    <0x1878 0x00000000>,
			    <0x187c 0x00000000>,
			    <0x1880 0x00000000>,
			    <0x1884 0x00000000>,
			    <0x1888 0x00000000>,
			    <0x188c 0x00000000>,
			    <0x1890 0x00000000>,
			    <0x1894 0x00000000>,
			    <0x1898 0x00000000>,
			    <0x189c 0x00000000>,
			    <0x18a0 0x00000000>,
			    <0x18a4 0x00000000>,
			    <0x18a8 0x00000000>,
			    <0x18ac 0x00000000>,
			    <0x18b0 0x00000000>,
			    <0x18b4 0x00000000>,
			    <0x18b8 0x00000000>,
			    <0x18bc 0x00000000>;

			  ime_reg_cfg = 
			    <0x0004 0x1800240e>,
			    <0x0008 0x00000205>,
			    <0x000c 0x800000dc>,
			    <0x0010 0x00000000>,
			    <0x0014 0x00000000>,
			    <0x0018 0x20004001>,
			    <0x001c 0x00000000>,
			    <0x0020 0x05f00a80>,
			    <0x0024 0x000101f0>,
			    <0x0028 0x002a0000>,
			    <0x002c 0x80c005f0>,
			    <0x0030 0x00000000>,
			    <0x0034 0x00000000>,
			    <0x0038 0x00000000>,
			    <0x003c 0x00000000>,
			    <0x0040 0x00000000>,
			    <0x0044 0x00000000>,
			    <0x0048 0x00000000>,
			    <0x004c 0x00000000>,
			    <0x0050 0x00000000>,
			    <0x0054 0x00000000>,
			    <0x0058 0x000002a0>,
			    <0x005c 0x00000000>,
			    <0x0060 0x00000000>,
			    <0x0064 0x00000001>,
			    <0x0068 0x00000000>,
			    <0x006c 0x00000000>,
			    <0x0070 0x00000000>,
			    <0x0074 0x00000000>,
			    <0x0078 0x00000000>,
			    <0x007c 0x00000000>,
			    <0x0080 0x00000000>,
			    <0x0084 0x00000012>,
			    <0x0088 0x00000000>,
			    <0x008c 0x00000000>,
			    <0x0090 0x00000000>,
			    <0x0094 0x00000000>,
			    <0x0098 0x00000000>,
			    <0x009c 0x05f00a80>,
			    <0x00a0 0x00000000>,
			    <0x00a4 0x05f00a80>,
			    <0x00a8 0x00000000>,
			    <0x00ac 0xff00ff00>,
			    <0x00b0 0x00000a80>,
			    <0x00b4 0x00000a80>,
			    <0x00b8 0x191a7000>,
			    <0x00bc 0x1958c800>,
			    <0x00c0 0x00000000>,
			    <0x00c4 0x00000000>,
			    <0x00c8 0x00000000>,
			    <0x00cc 0x00000000>,
			    <0x00d0 0x00000000>,
			    <0x00d4 0x00000000>,
			    <0x00d8 0x00000000>,
			    <0x00dc 0x00000000>,
			    <0x00e0 0x00000000>,
			    <0x00e4 0x00000000>,
			    <0x00e8 0x00000000>,
			    <0x00ec 0x00000000>,
			    <0x00f0 0x00000000>,
			    <0x00f4 0x00000000>,
			    <0x00f8 0x00000000>,
			    <0x00fc 0x00000000>,
			    <0x0100 0x0000001c>,
			    <0x0104 0x1766810c>,
			    <0x0108 0x2bd3347b>,
			    <0x010c 0x032c0435>,
			    <0x0110 0x050d03cf>,
			    <0x0114 0x050b03ce>,
			    <0x0118 0x050a03cd>,
			    <0x011c 0x00000000>,
			    <0x0120 0x00000000>,
			    <0x0124 0x00000000>,
			    <0x0128 0x00000000>,
			    <0x012c 0x00000000>,
			    <0x0130 0x00000000>,
			    <0x0134 0x00000000>,
			    <0x0138 0x00000000>,
			    <0x013c 0x00000000>,
			    <0x0140 0x00000000>,
			    <0x0144 0x01e00280>,
			    <0x0148 0x00000000>,
			    <0x014c 0x01e00280>,
			    <0x0150 0x00000000>,
			    <0x0154 0xff00ff00>,
			    <0x0158 0x00000280>,
			    <0x015c 0x00000280>,
			    <0x0160 0x1a97d000>,
			    <0x0164 0x1a9c8000>,
			    <0x0168 0x00000000>,
			    <0x016c 0x00000000>,
			    <0x0170 0x00000000>,
			    <0x0174 0x00000000>,
			    <0x0178 0x00000000>,
			    <0x017c 0x00000000>,
			    <0x0180 0x00000000>,
			    <0x0184 0x00000000>,
			    <0x0188 0x00000000>,
			    <0x018c 0x00000000>,
			    <0x0190 0x00000000>,
			    <0x0194 0x00000000>,
			    <0x0198 0x00000000>,
			    <0x019c 0x00000000>,
			    <0x01a0 0x00000000>,
			    <0x01a4 0x00000000>,
			    <0x01a8 0x00000000>,
			    <0x01ac 0x00000000>,
			    <0x01b0 0x00000000>,
			    <0x01b4 0x00000000>,
			    <0x01b8 0x00000000>,
			    <0x01bc 0x00000000>,
			    <0x01c0 0x00000000>,
			    <0x01c4 0x00000000>,
			    <0x01c8 0x00000000>,
			    <0x01cc 0x00000000>,
			    <0x01d0 0x00000000>,
			    <0x01d4 0x00000000>,
			    <0x01d8 0x00000000>,
			    <0x01dc 0x00000000>,
			    <0x01e0 0x00000000>,
			    <0x01e4 0x00000000>,
			    <0x01e8 0x00000000>,
			    <0x01ec 0x00000000>,
			    <0x01f0 0x00000000>,
			    <0x01f4 0x00000000>,
			    <0x01f8 0x00000000>,
			    <0x01fc 0x00000000>,
			    <0x0200 0x00000000>,
			    <0x0204 0xff00ff00>,
			    <0x0208 0x00000000>,
			    <0x020c 0x00000000>,
			    <0x0210 0x00000000>,
			    <0x0214 0x00000000>,
			    <0x0218 0x00000000>,
			    <0x021c 0x00000000>,
			    <0x0220 0x00000000>,
			    <0x0224 0x00000000>,
			    <0x0228 0x00000000>,
			    <0x022c 0x00000000>,
			    <0x0230 0x00000000>,
			    <0x0234 0x00000000>,
			    <0x0238 0x00000000>,
			    <0x023c 0x00000000>,
			    <0x0240 0x00000000>,
			    <0x0244 0x00000000>,
			    <0x0248 0x00000000>,
			    <0x024c 0x00000000>,
			    <0x0250 0x00000000>,
			    <0x0254 0x00000000>,
			    <0x0258 0x00000000>,
			    <0x025c 0x00000000>,
			    <0x0260 0x00000000>,
			    <0x0264 0x00000000>,
			    <0x0268 0x00000000>,
			    <0x026c 0x00000000>,
			    <0x0270 0x00000000>,
			    <0x0274 0x00000000>,
			    <0x0278 0x00000000>,
			    <0x027c 0x00000000>,
			    <0x0280 0x00000000>,
			    <0x0284 0x00000000>,
			    <0x0288 0x00000000>,
			    <0x028c 0x00000000>,
			    <0x0290 0x00000000>,
			    <0x0294 0x00000000>,
			    <0x0298 0x00000000>,
			    <0x029c 0x00000000>,
			    <0x02a0 0x00000000>,
			    <0x02a4 0x00000000>,
			    <0x02a8 0x00000000>,
			    <0x02ac 0x00000000>,
			    <0x02b0 0x00000000>,
			    <0x02b4 0xff00ff00>,
			    <0x02b8 0x00000000>,
			    <0x02bc 0x00000000>,
			    <0x02c0 0x00000000>,
			    <0x02c4 0x00000000>,
			    <0x02c8 0x00000000>,
			    <0x02cc 0x00000000>,
			    <0x02d0 0x00000000>,
			    <0x02d4 0x00000000>,
			    <0x02d8 0x00000000>,
			    <0x02dc 0x00000000>,
			    <0x02e0 0x00000000>,
			    <0x02e4 0x00000000>,
			    <0x02e8 0x00000000>,
			    <0x02ec 0x00000000>,
			    <0x02f0 0x00000000>,
			    <0x02f4 0x00000000>,
			    <0x02f8 0x00000000>,
			    <0x02fc 0x00000000>,
			    <0x0300 0x00000000>,
			    <0x0304 0x00000000>,
			    <0x0308 0x00000000>,
			    <0x030c 0x00000000>,
			    <0x0310 0x017c02a0>,
			    <0x0314 0x00000000>,
			    <0x0318 0x00000000>,
			    <0x031c 0x00000000>,
			    <0x0320 0x00000000>,
			    <0x0324 0x00000000>,
			    <0x0328 0x00000000>,
			    <0x032c 0x00000000>,
			    <0x0330 0x00000000>,
			    <0x0334 0x00000000>,
			    <0x0338 0x00000000>,
			    <0x033c 0x00000000>,
			    <0x0340 0x00000000>,
			    <0x0344 0x00000000>,
			    <0x0348 0x00000000>,
			    <0x034c 0x00000000>,
			    <0x0350 0x00000000>,
			    <0x0354 0x00000000>,
			    <0x0358 0x00000000>,
			    <0x035c 0x00000000>,
			    <0x0360 0x00000000>,
			    <0x0364 0x00000000>,
			    <0x0368 0x00000000>,
			    <0x036c 0x00000000>,
			    <0x0370 0x00000000>,
			    <0x0374 0x00000000>,
			    <0x0378 0x00000000>,
			    <0x037c 0x00000000>,
			    <0x0380 0x00008080>,
			    <0x0384 0x16c6b9f0>,
			    <0x0388 0x0a63a12a>,
			    <0x038c 0x00008864>,
			    <0x0390 0x16c6b9f0>,
			    <0x0394 0x0a63a12a>,
			    <0x0398 0x00008864>,
			    <0x039c 0x00000000>,
			    <0x03a0 0x00000000>,
			    <0x03a4 0x00000000>,
			    <0x03a8 0x00000000>,
			    <0x03ac 0x00000000>,
			    <0x03b0 0x00000000>,
			    <0x03b4 0x00000000>,
			    <0x03b8 0x00000000>,
			    <0x03bc 0x00000000>,
			    <0x03c0 0x00000000>,
			    <0x03c4 0x00000000>,
			    <0x03c8 0x00000000>,
			    <0x03cc 0x00000000>,
			    <0x03d0 0x00000000>,
			    <0x03d4 0x00000000>,
			    <0x03d8 0x00000000>,
			    <0x03dc 0x00000000>,
			    <0x03e0 0x00000000>,
			    <0x03e4 0x00000000>,
			    <0x03e8 0x00000000>,
			    <0x03ec 0x00000000>,
			    <0x03f0 0x00000000>,
			    <0x03f4 0x00000000>,
			    <0x03f8 0x00000000>,
			    <0x03fc 0x00000000>,
			    <0x0400 0x00000000>,
			    <0x0404 0x00000000>,
			    <0x0408 0x00000000>,
			    <0x040c 0x00000000>,
			    <0x0410 0x00000000>,
			    <0x0414 0x00000000>,
			    <0x0418 0x00000000>,
			    <0x041c 0x00000000>,
			    <0x0420 0x00000000>,
			    <0x0424 0x00000000>,
			    <0x0428 0x00000000>,
			    <0x042c 0x00000000>,
			    <0x0430 0x00000000>,
			    <0x0434 0x00000000>,
			    <0x0438 0x00000000>,
			    <0x043c 0x00000000>,
			    <0x0440 0x00000000>,
			    <0x0444 0x00000000>,
			    <0x0448 0x00000000>,
			    <0x044c 0x00000000>,
			    <0x0450 0x00000000>,
			    <0x0454 0x00000000>,
			    <0x0458 0x00000000>,
			    <0x045c 0x00000000>,
			    <0x0460 0x00000000>,
			    <0x0464 0x00000000>,
			    <0x0468 0x00000000>,
			    <0x046c 0x00000000>,
			    <0x0470 0x00000000>,
			    <0x0474 0x00000000>,
			    <0x0478 0x00000000>,
			    <0x047c 0x00000000>,
			    <0x0480 0x00000000>,
			    <0x0484 0x00000000>,
			    <0x0488 0x00000000>,
			    <0x048c 0x00000000>,
			    <0x0490 0x000005a1>,
			    <0x0494 0x00026ac0>,
			    <0x0498 0x00c005a1>,
			    <0x049c 0x0002d000>,
			    <0x04a0 0x00000000>,
			    <0x04a4 0x00000000>,
			    <0x04a8 0x00000000>,
			    <0x04ac 0x00000000>,
			    <0x04b0 0x00000000>,
			    <0x04b4 0x00000000>,
			    <0x04b8 0x00000000>,
			    <0x04bc 0x00000000>,
			    <0x04c0 0x00000000>,
			    <0x04c4 0x00000000>,
			    <0x04c8 0x00000000>,
			    <0x04cc 0x00000000>,
			    <0x04d0 0x0ff554e8>,
			    <0x04d4 0x80c205a1>,
			    <0x04d8 0xc4023820>,
			    <0x04dc 0x824205a1>,
			    <0x04e0 0x0402bf20>,
			    <0x04e4 0x824005a1>,
			    <0x04e8 0x00018f60>,
			    <0x04ec 0x80c005a1>,
			    <0x04f0 0x00021660>,
			    <0x04f4 0x00000000>,
			    <0x04f8 0x024005a1>,
			    <0x04fc 0x0003bc40>,
			    <0x0500 0x024205a1>,
			    <0x0504 0x04009240>,
			    <0x0508 0x00c205a1>,
			    <0x050c 0x04017e80>,
			    <0x0510 0x000205a1>,
			    <0x0514 0x0401e3c0>,
			    <0x0518 0x0142a930>,
			    <0x051c 0x81900001>,
			    <0x0520 0x40000000>,
			    <0x0524 0x00000781>,
			    <0x0528 0x00011940>,
			    <0x052c 0x01900001>,
			    <0x0530 0x00002ee0>,
			    <0x0534 0x00020781>,
			    <0x0538 0x0400ea60>,
			    <0x053c 0x00000000>,
			    <0x0540 0x81680001>,
			    <0x0544 0x040001c2>,
			    <0x0548 0x000006e1>,
			    <0x054c 0x0000ffaa>,
			    <0x0550 0x01680001>,
			    <0x0554 0x0000286e>,
			    <0x0558 0x000206e1>,
			    <0x055c 0x0400d8fe>,
			    <0x0560 0x00ff00ff>,
			    <0x0564 0x00000000>,
			    <0x0568 0x00000000>,
			    <0x056c 0x00000000>,
			    <0x0570 0x00000000>,
			    <0x0574 0x00000000>,
			    <0x0578 0x00000000>,
			    <0x057c 0x00000000>,
			    <0x0580 0x00000000>,
			    <0x0584 0x00000000>,
			    <0x0588 0x00000000>,
			    <0x058c 0x00000000>,
			    <0x0590 0x00000000>,
			    <0x0594 0x00000000>,
			    <0x0598 0x00000000>,
			    <0x059c 0x00000000>,
			    <0x05a0 0x00000000>,
			    <0x05a4 0x00000000>,
			    <0x05a8 0x00000000>,
			    <0x05ac 0x00000000>,
			    <0x05b0 0x00000000>,
			    <0x05b4 0x00000000>,
			    <0x05b8 0x00000000>,
			    <0x05bc 0x00000000>,
			    <0x05c0 0x00000000>,
			    <0x05c4 0x00000000>,
			    <0x05c8 0x00000000>,
			    <0x05cc 0x00000000>,
			    <0x05d0 0x00000000>,
			    <0x05d4 0x00000000>,
			    <0x05d8 0x00000000>,
			    <0x05dc 0x00000000>,
			    <0x05e0 0x00000000>,
			    <0x05e4 0x00000000>,
			    <0x05e8 0x00000000>,
			    <0x05ec 0x00000000>,
			    <0x05f0 0x00000000>,
			    <0x05f4 0x00000000>,
			    <0x05f8 0x00000000>,
			    <0x05fc 0x00000000>,
			    <0x0600 0x00000000>,
			    <0x0604 0x00000000>,
			    <0x0608 0x00000000>,
			    <0x060c 0x00000000>,
			    <0x0610 0x00000000>,
			    <0x0614 0x00000000>,
			    <0x0618 0x00000000>,
			    <0x061c 0x00000000>,
			    <0x0620 0x00000000>,
			    <0x0624 0x00000000>,
			    <0x0628 0x00000000>,
			    <0x062c 0x00000000>,
			    <0x0630 0x00000000>,
			    <0x0634 0x00000000>,
			    <0x0638 0x00000000>,
			    <0x063c 0x00000000>,
			    <0x0640 0x00000000>,
			    <0x0644 0x00000000>,
			    <0x0648 0x00000000>,
			    <0x064c 0x00000000>,
			    <0x0650 0x00000000>,
			    <0x0654 0x00000000>,
			    <0x0658 0x00000000>,
			    <0x065c 0x00000000>,
			    <0x0660 0x00000000>,
			    <0x0664 0x00000000>,
			    <0x0668 0x00000000>,
			    <0x066c 0x00000000>,
			    <0x0670 0x00000000>,
			    <0x0674 0x00000000>,
			    <0x0678 0x00000000>,
			    <0x067c 0x00000000>,
			    <0x0680 0x00000000>,
			    <0x0684 0x00000000>,
			    <0x0688 0x00000000>,
			    <0x068c 0x00000000>,
			    <0x0690 0x00000000>,
			    <0x0694 0x00000000>,
			    <0x0698 0x00000000>,
			    <0x069c 0x00000000>,
			    <0x06a0 0x00000000>,
			    <0x06a4 0x00000000>,
			    <0x06a8 0x00000000>,
			    <0x06ac 0x00000000>,
			    <0x06b0 0x00000000>,
			    <0x06b4 0x00000000>,
			    <0x06b8 0x00000000>,
			    <0x06bc 0x00000000>,
			    <0x06c0 0x00000000>,
			    <0x06c4 0x00000000>,
			    <0x06c8 0x00000000>,
			    <0x06cc 0x00000000>,
			    <0x06d0 0x00000000>,
			    <0x06d4 0x00000000>,
			    <0x06d8 0x00000000>,
			    <0x06dc 0x00000000>,
			    <0x06e0 0x00000000>,
			    <0x06e4 0x00000000>,
			    <0x06e8 0x00000000>,
			    <0x06ec 0x00000000>,
			    <0x06f0 0x00000000>,
			    <0x06f4 0x00000000>,
			    <0x06f8 0x00000000>,
			    <0x06fc 0x00000000>,
			    <0x0700 0x00300f22>,
			    <0x0704 0x00000000>,
			    <0x0708 0x00000000>,
			    <0x070c 0x00000000>,
			    <0x0710 0x00000000>,
			    <0x0714 0x00000000>,
			    <0x0718 0x00000000>,
			    <0x071c 0x00000000>,
			    <0x0720 0x00000000>,
			    <0x0724 0x00000000>,
			    <0x0728 0x00008020>,
			    <0x072c 0x0320c832>,
			    <0x0730 0x00010842>,
			    <0x0734 0x06060606>,
			    <0x0738 0x08070706>,
			    <0x073c 0x000008b4>,
			    <0x0740 0x44444344>,
			    <0x0744 0x001033ff>,
			    <0x0748 0x00000000>,
			    <0x074c 0x00000000>,
			    <0x0750 0x00000000>,
			    <0x0754 0x00000014>,
			    <0x0758 0x00000000>,
			    <0x075c 0x00000000>,
			    <0x0760 0x07070807>,
			    <0x0764 0x06060606>,
			    <0x0768 0x005a0050>,
			    <0x076c 0x00460050>,
			    <0x0770 0x003c003c>,
			    <0x0774 0x003c003c>,
			    <0x0778 0x001e0019>,
			    <0x077c 0x00140019>,
			    <0x0780 0x00140014>,
			    <0x0784 0x00140014>,
			    <0x0788 0x00001008>,
			    <0x078c 0x00000000>,
			    <0x0790 0x00000000>,
			    <0x0794 0x00000000>,
			    <0x0798 0x00000000>,
			    <0x079c 0x00000000>,
			    <0x07a0 0x00c800c8>,
			    <0x07a4 0x006400c8>,
			    <0x07a8 0x00640064>,
			    <0x07ac 0x00640064>,
			    <0x07b0 0x07070807>,
			    <0x07b4 0x06060606>,
			    <0x07b8 0x005a0050>,
			    <0x07bc 0x00460050>,
			    <0x07c0 0x003c003c>,
			    <0x07c4 0x003c003c>,
			    <0x07c8 0x001e0019>,
			    <0x07cc 0x00140019>,
			    <0x07d0 0x00140014>,
			    <0x07d4 0x00140014>,
			    <0x07d8 0x00001008>,
			    <0x07dc 0x00000000>,
			    <0x07e0 0x00000000>,
			    <0x07e4 0x00000000>,
			    <0x07e8 0x00000000>,
			    <0x07ec 0x00000000>,
			    <0x07f0 0x00001008>,
			    <0x07f4 0x00000000>,
			    <0x07f8 0x00000000>,
			    <0x07fc 0x00000000>,
			    <0x0800 0x00c81008>,
			    <0x0804 0x10000000>,
			    <0x0808 0x00100000>,
			    <0x080c 0x00000000>,
			    <0x0810 0x00000000>,
			    <0x0814 0x00000000>,
			    <0x0818 0x00000000>,
			    <0x081c 0x00000000>,
			    <0x0820 0x3fff0403>,
			    <0x0824 0x00002010>,
			    <0x0828 0xffff0000>,
			    <0x082c 0x000001ff>,
			    <0x0830 0x00400040>,
			    <0x0834 0x00400040>,
			    <0x0838 0x00400040>,
			    <0x083c 0x00400040>,
			    <0x0840 0x00000000>,
			    <0x0844 0x00000000>,
			    <0x0848 0x00000000>,
			    <0x084c 0x00000000>,
			    <0x0850 0x00000603>,
			    <0x0854 0x00000000>,
			    <0x0858 0x00000000>,
			    <0x085c 0x01020201>,
			    <0x0860 0x20202020>,
			    <0x0864 0x00000000>,
			    <0x0868 0x00000000>,
			    <0x086c 0x00000000>,
			    <0x0870 0x00000000>,
			    <0x0874 0x00000000>,
			    <0x0878 0x00000000>,
			    <0x087c 0x00000000>,
			    <0x0880 0x10101010>,
			    <0x0884 0x10101010>,
			    <0x0888 0x00000000>,
			    <0x088c 0x00000000>,
			    <0x0890 0x00000000>,
			    <0x0894 0x00000000>,
			    <0x0898 0x00000000>,
			    <0x089c 0x00000000>,
			    <0x08a0 0x0e0c0a08>,
			    <0x08a4 0x00000000>,
			    <0x08a8 0x00000000>,
			    <0x08ac 0x00000000>,
			    <0x08b0 0x10001040>,
			    <0x08b4 0x02041020>,
			    <0x08b8 0x00d6013a>,
			    <0x08bc 0x00002040>,
			    <0x08c0 0x2b180c00>,
			    <0x08c4 0x7060503e>,
			    <0x08c8 0x28160900>,
			    <0x08cc 0x70604b39>,
			    <0x08d0 0x00004080>,
			    <0x08d4 0x00000000>,
			    <0x08d8 0x00000000>,
			    <0x08dc 0x00000000>,
			    <0x08e0 0x00000000>,
			    <0x08e4 0x00000000>,
			    <0x08e8 0x00000000>,
			    <0x08ec 0x00000000>,
			    <0x08f0 0x00000000>,
			    <0x08f4 0x00000000>,
			    <0x08f8 0x00000000>,
			    <0x08fc 0x00000000>,
			    <0x0900 0x00000a80>,
			    <0x0904 0x00000a80>,
			    <0x0908 0x18bce000>,
			    <0x090c 0x18fb3800>,
			    <0x0910 0x00000000>,
			    <0x0914 0x00000000>,
			    <0x0918 0x00000000>,
			    <0x091c 0x00000000>,
			    <0x0920 0x00000018>,
			    <0x0924 0x1afc0600>,
			    <0x0928 0x00000000>,
			    <0x092c 0x1afc0f00>,
			    <0x0930 0x00000018>,
			    <0x0934 0x1afc2100>,
			    <0x0938 0x000002a0>,
			    <0x093c 0x1af44000>,
			    <0x0940 0x00000000>,
			    <0x0944 0x1af82300>,
			    <0x0948 0x00000000>,
			    <0x094c 0x00000000>,
			    <0x0950 0x00000000>,
			    <0x0954 0x00000000>,
			    <0x0958 0x00000000>,
			    <0x095c 0x00000000>,
			    <0x0960 0x00000000>,
			    <0x0964 0x00000000>,
			    <0x0968 0x00000000>,
			    <0x096c 0x00000000>,
			    <0x0970 0x00000000>,
			    <0x0974 0x00000000>,
			    <0x0978 0x00000000>,
			    <0x097c 0x00000000>,
			    <0x0980 0x00000000>,
			    <0x0984 0x00000000>,
			    <0x0988 0x00000000>,
			    <0x098c 0x00000000>,
			    <0x0990 0x00000000>,
			    <0x0994 0x00000000>,
			    <0x0998 0x00000000>,
			    <0x099c 0x00000000>,
			    <0x09a0 0x00000000>,
			    <0x09a4 0x00000000>,
			    <0x09a8 0x00000000>,
			    <0x09ac 0x00000000>,
			    <0x09b0 0x00000000>,
			    <0x09b4 0x00000000>,
			    <0x09b8 0x00000000>,
			    <0x09bc 0x00000000>,
			    <0x09c0 0x00000000>,
			    <0x09c4 0x00000000>,
			    <0x09c8 0x00000000>,
			    <0x09cc 0x00000000>,
			    <0x09d0 0x00000000>,
			    <0x09d4 0x00000000>,
			    <0x09d8 0x00000000>,
			    <0x09dc 0x00000000>,
			    <0x09e0 0x00000000>,
			    <0x09e4 0xff00ff00>,
			    <0x09e8 0x00000000>,
			    <0x09ec 0x00000000>,
			    <0x09f0 0x00000000>,
			    <0x09f4 0x00000000>,
			    <0x09f8 0x00000000>,
			    <0x09fc 0x00000000>,
			    <0x0a00 0x00000000>,
			    <0x0a04 0x00000000>,
			    <0x0a08 0x75614e3a>,
			    <0x0a0c 0xc3af9c88>,
			    <0x0a10 0x05040301>,
			    <0x0a14 0x09080706>,
			    <0x0a18 0x0d0c0b0a>,
			    <0x0a1c 0x13100f0e>,
			    <0x0a20 0x00000000>,
			    <0x0a24 0x00000000>,
			    <0x0a28 0x00000000>,
			    <0x0a2c 0x00000000>,
			    <0x0a30 0x00000000>,
			    <0x0a34 0x00000000>,
			    <0x0a38 0x00000000>,
			    <0x0a3c 0x00000000>,
			    <0x0a40 0x00000000>,
			    <0x0a44 0x00000000>,
			    <0x0a48 0x00000000>,
			    <0x0a4c 0x00000000>,
			    <0x0a50 0x00000000>,
			    <0x0a54 0x00000000>,
			    <0x0a58 0x00000000>,
			    <0x0a5c 0x00000000>,
			    <0x0a60 0x00000000>,
			    <0x0a64 0x00000000>,
			    <0x0a68 0x00000000>,
			    <0x0a6c 0x00000000>,
			    <0x0a70 0x00000000>,
			    <0x0a74 0x00000000>,
			    <0x0a78 0x00000000>,
			    <0x0a7c 0x00000000>,
			    <0x0a80 0x00000000>,
			    <0x0a84 0x00000000>,
			    <0x0a88 0x00000000>,
			    <0x0a8c 0x00000000>,
			    <0x0a90 0x00000000>,
			    <0x0a94 0x00000000>,
			    <0x0a98 0x00000000>,
			    <0x0a9c 0x00000000>,
			    <0x0aa0 0x00000000>,
			    <0x0aa4 0x00000000>,
			    <0x0aa8 0x00000000>,
			    <0x0aac 0x00000000>,
			    <0x0ab0 0x00000000>,
			    <0x0ab4 0x00000000>,
			    <0x0ab8 0x00000000>,
			    <0x0abc 0x00000000>,
			    <0x0ac0 0x00000000>,
			    <0x0ac4 0x00000000>,
			    <0x0ac8 0x00000000>,
			    <0x0acc 0x00000000>,
			    <0x0ad0 0x00000000>,
			    <0x0ad4 0x00000000>,
			    <0x0ad8 0x00000000>,
			    <0x0adc 0x00000000>,
			    <0x0ae0 0x00000000>,
			    <0x0ae4 0x00000000>,
			    <0x0ae8 0x00000000>,
			    <0x0aec 0x00000000>,
			    <0x0af0 0x00000000>,
			    <0x0af4 0x00000000>,
			    <0x0af8 0x00000000>,
			    <0x0afc 0x00000000>,
			    <0x0b00 0x00000000>,
			    <0x0b04 0x00000000>,
			    <0x0b08 0x00000000>,
			    <0x0b0c 0x00000000>,
			    <0x0b10 0x00000000>,
			    <0x0b14 0x00000000>,
			    <0x0b18 0x00000000>,
			    <0x0b1c 0x00000000>,
			    <0x0b20 0x00000000>,
			    <0x0b24 0x00000000>,
			    <0x0b28 0x00000000>,
			    <0x0b2c 0x00000000>,
			    <0x0b30 0x00000000>,
			    <0x0b34 0x00000000>,
			    <0x0b38 0x00000000>,
			    <0x0b3c 0x00000000>,
			    <0x0b40 0x00000000>,
			    <0x0b44 0x00000000>,
			    <0x0b48 0x00000000>,
			    <0x0b4c 0x00000000>,
			    <0x0b50 0x00000000>,
			    <0x0b54 0x00000000>,
			    <0x0b58 0x00000000>,
			    <0x0b5c 0x00000000>,
			    <0x0b60 0x00000000>,
			    <0x0b64 0x00000000>,
			    <0x0b68 0x00000000>,
			    <0x0b6c 0x00000000>,
			    <0x0b70 0x00000631>,
			    <0x0b74 0x00000000>,
			    <0x0b78 0x00030202>,
			    <0x0b7c 0x00030202>,
			    <0x0b80 0x08200820>,
			    <0x0b84 0x00000000>,
			    <0x0b88 0x00000000>,
			    <0x0b8c 0x005a0040>,
			    <0x0b90 0x0080006e>,
			    <0x0b94 0x0000008f>,
			    <0x0b98 0x00000000>,
			    <0x0b9c 0x00000000>,
			    <0x0ba0 0x00050004>,
			    <0x0ba4 0x00080006>,
			    <0x0ba8 0x00000008>,
			    <0x0bac 0x00000000>,
			    <0x0bb0 0x00000000>,
			    <0x0bb4 0x23591900>,
			    <0x0bb8 0x32002b4c>,
			    <0x0bbc 0x820037e6>,
			    <0x0bc0 0x00202020>,
			    <0x0bc4 0x00202020>,
			    <0x0bc8 0x001f1f1e>,
			    <0x0bcc 0x00020202>,
			    <0x0bd0 0x001f1f1e>,
			    <0x0bd4 0x00020202>,
			    <0x0bd8 0x00000000>,
			    <0x0bdc 0x00000000>,
			    <0x0be0 0x00030301>,
			    <0x0be4 0x00010101>,
			    <0x0be8 0x00030301>,
			    <0x0bec 0x00010101>,
			    <0x0bf0 0x05400000>,
			    <0x0bf4 0x00000064>,
			    <0x0bf8 0x00000064>,
			    <0x0bfc 0x00000000>,
			    <0x0c00 0x00000000>,
			    <0x0c04 0x00000000>,
			    <0x0c08 0x00000000>,
			    <0x0c0c 0x00000000>,
			    <0x0c10 0x00000000>,
			    <0x0c14 0x00000000>,
			    <0x0c18 0x00000000>,
			    <0x0c1c 0x00000000>,
			    <0x0c20 0x00000000>,
			    <0x0c24 0x00000000>,
			    <0x0c28 0x00000000>,
			    <0x0c2c 0x00000000>,
			    <0x0c30 0x00000000>,
			    <0x0c34 0x00000000>,
			    <0x0c38 0x00000000>,
			    <0x0c3c 0x00000000>,
			    <0x0c40 0x00000000>,
			    <0x0c44 0x00000000>,
			    <0x0c48 0x00000000>,
			    <0x0c4c 0x00000000>,
			    <0x0c50 0x00000000>,
			    <0x0c54 0x00000000>,
			    <0x0c58 0x00000000>,
			    <0x0c5c 0x00000000>,
			    <0x0c60 0x00000000>,
			    <0x0c64 0x00000000>,
			    <0x0c68 0x00000000>,
			    <0x0c6c 0x00000000>,
			    <0x0c70 0x00000000>,
			    <0x0c74 0x00000000>,
			    <0x0c78 0x00000000>,
			    <0x0c7c 0x00000000>,
			    <0x0c80 0x00000000>,
			    <0x0c84 0x00000000>,
			    <0x0c88 0x00000000>,
			    <0x0c8c 0x00000000>;

			};
		};
	};
};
